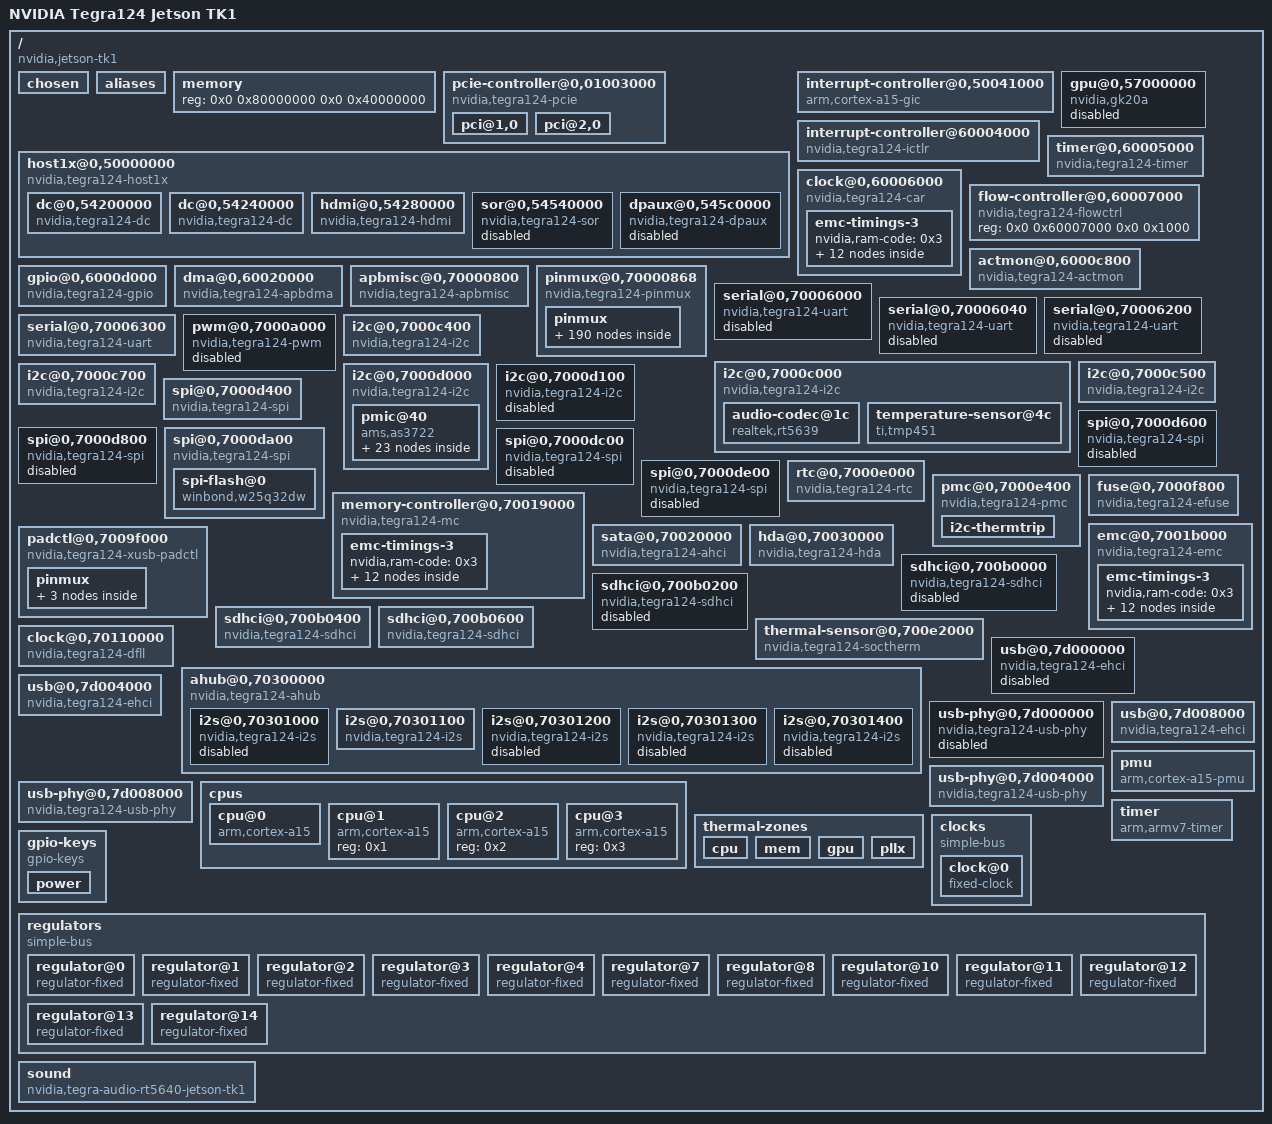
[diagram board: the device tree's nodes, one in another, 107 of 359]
/*
 * Modified from Linux device tree "arch/arm/boot/dts/tegra124-jetson-tk1.dts"
 *
 * The code contained herein is licensed under the GNU General Public
 * License. You may obtain a copy of the GNU General Public License
 * Version 2 or later at the following locations:
 *
 * http://www.opensource.org/licenses/gpl-license.html
 * http://www.gnu.org/copyleft/gpl.html
 *
 * @TAG(OTHER_GPL)
 */

/dts-v1/;

/ {
	#address-cells = <0x2>;
	#size-cells = <0x2>;
	compatible = "nvidia,jetson-tk1", "nvidia,tegra124";
	model = "NVIDIA Tegra124 Jetson TK1";
	interrupt-parent = <0x1>;

	chosen {
		bootargs = "console=ttyS0,115200n8 otf_key=c75e5bb91eb3bd947560357b64422f85 usbcore.old_scheme_first=1 tegraid=40.1.1.0.0 modem_id=0 android.kerneltype=normal commchip_id=0 usb_port_owner_info=2 lane_owner_info=1 touch_id=0@0 board_info=0x0177:0x0000:0x02:0x43:0x00 init=/sbin/init root=/dev/mmcblk0p2 rw rootwait gpt earlyprintk";
	};

	aliases {
		rtc0 = "/i2c@0,7000d000/pmic@40";
		rtc1 = "/rtc@0,7000e000";
		serial0 = "/serial@0,70006300";
	};

	memory {
		device_type = "memory";
		reg = <0x0 0x80000000 0x0 0x40000000>;
	};

	pcie-controller@0,01003000 {
		compatible = "nvidia,tegra124-pcie";
		device_type = "pci";
		reg = <0x0 0x1003000 0x0 0x800 0x0 0x1003800 0x0 0x800 0x0 0x2000000 0x0 0x10000000>;
		reg-names = "pads", "afi", "cs";
		interrupts = <0x0 0x62 0x4 0x0 0x63 0x4>;
		interrupt-names = "intr", "msi";
		#interrupt-cells = <0x1>;
		interrupt-map-mask = <0x0 0x0 0x0 0x0>;
		interrupt-map = <0x0 0x0 0x0 0x0 0x1 0x0 0x62 0x4>;
		bus-range = <0x0 0xff>;
		#address-cells = <0x3>;
		#size-cells = <0x2>;
		ranges = <0x82000000 0x0 0x1000000 0x0 0x1000000 0x0 0x1000 0x82000000 0x0 0x1001000 0x0 0x1001000 0x0 0x1000 0x81000000 0x0 0x0 0x0 0x12000000 0x0 0x10000 0x82000000 0x0 0x13000000 0x0 0x13000000 0x0 0xd000000 0xc2000000 0x0 0x20000000 0x0 0x20000000 0x0 0x20000000>;
		clocks = <0x2 0x46 0x2 0x48 0x2 0xe7 0x2 0x10c>;
		clock-names = "pex", "afi", "pll_e", "cml";
		resets = <0x2 0x46 0x2 0x48 0x2 0x4a>;
		reset-names = "pex", "afi", "pcie_x";
		status = "okay";
		phys = <0x3 0x0>;
		phy-names = "pcie";
		avddio-pex-supply = <0x4>;
		dvddio-pex-supply = <0x4>;
		avdd-pex-pll-supply = <0x4>;
		hvdd-pex-supply = <0x5>;
		hvdd-pex-pll-e-supply = <0x5>;
		vddio-pex-ctl-supply = <0x5>;
		avdd-pll-erefe-supply = <0x6>;

		pci@1,0 {
			device_type = "pci";
			assigned-addresses = <0x82000800 0x0 0x1000000 0x0 0x1000>;
			reg = <0x800 0x0 0x0 0x0 0x0>;
			status = "okay";
			#address-cells = <0x3>;
			#size-cells = <0x2>;
			ranges;
			nvidia,num-lanes = <0x2>;
		};

		pci@2,0 {
			device_type = "pci";
			assigned-addresses = <0x82001000 0x0 0x1001000 0x0 0x1000>;
			reg = <0x1000 0x0 0x0 0x0 0x0>;
			status = "okay";
			#address-cells = <0x3>;
			#size-cells = <0x2>;
			ranges;
			nvidia,num-lanes = <0x1>;
		};
	};

	host1x@0,50000000 {
		compatible = "nvidia,tegra124-host1x", "simple-bus";
		reg = <0x0 0x50000000 0x0 0x34000>;
		interrupts = <0x0 0x41 0x4 0x0 0x43 0x4>;
		clocks = <0x2 0x1c>;
		resets = <0x2 0x1c>;
		reset-names = "host1x";
		#address-cells = <0x2>;
		#size-cells = <0x2>;
		ranges = <0x0 0x54000000 0x0 0x54000000 0x0 0x1000000>;

		dc@0,54200000 {
			compatible = "nvidia,tegra124-dc";
			reg = <0x0 0x54200000 0x0 0x40000>;
			interrupts = <0x0 0x49 0x4>;
			clocks = <0x2 0x1b 0x2 0xd3>;
			clock-names = "dc", "parent";
			resets = <0x2 0x1b>;
			reset-names = "dc";
			iommus = <0x7 0x1>;
			nvidia,head = <0x0>;
		};

		dc@0,54240000 {
			compatible = "nvidia,tegra124-dc";
			reg = <0x0 0x54240000 0x0 0x40000>;
			interrupts = <0x0 0x4a 0x4>;
			clocks = <0x2 0x1a 0x2 0xd3>;
			clock-names = "dc", "parent";
			resets = <0x2 0x1a>;
			reset-names = "dc";
			iommus = <0x7 0x2>;
			nvidia,head = <0x1>;
		};

		hdmi@0,54280000 {
			compatible = "nvidia,tegra124-hdmi";
			reg = <0x0 0x54280000 0x0 0x40000>;
			interrupts = <0x0 0x4b 0x4>;
			clocks = <0x2 0x33 0x2 0xdd>;
			clock-names = "hdmi", "parent";
			resets = <0x2 0x33>;
			reset-names = "hdmi";
			status = "okay";
			hdmi-supply = <0x8>;
			pll-supply = <0x9>;
			vdd-supply = <0xa>;
			nvidia,ddc-i2c-bus = <0xb>;
			nvidia,hpd-gpio = <0xc 0x6f 0x0>;
		};

		sor@0,54540000 {
			compatible = "nvidia,tegra124-sor";
			reg = <0x0 0x54540000 0x0 0x40000>;
			interrupts = <0x0 0x4c 0x4>;
			clocks = <0x2 0xb6 0x2 0xdb 0x2 0x10f 0x2 0xc9>;
			clock-names = "sor", "parent", "dp", "safe";
			resets = <0x2 0xb6>;
			reset-names = "sor";
			status = "disabled";
		};

		dpaux@0,545c0000 {
			compatible = "nvidia,tegra124-dpaux";
			reg = <0x0 0x545c0000 0x0 0x40000>;
			interrupts = <0x0 0x9f 0x4>;
			clocks = <0x2 0xb5 0x2 0x10f>;
			clock-names = "dpaux", "parent";
			resets = <0x2 0xb5>;
			reset-names = "dpaux";
			status = "disabled";
		};
	};

	interrupt-controller@0,50041000 {
		compatible = "arm,cortex-a15-gic";
		#interrupt-cells = <0x3>;
		interrupt-controller;
		reg = <0x0 0x50041000 0x0 0x1000 0x0 0x50042000 0x0 0x1000 0x0 0x50044000 0x0 0x2000 0x0 0x50046000 0x0 0x2000>;
		interrupts = <0x1 0x9 0xf04>;
		interrupt-parent = <0x1>;
		linux,phandle = <0x1>;
		phandle = <0x1>;
	};

	gpu@0,57000000 {
		compatible = "nvidia,gk20a";
		reg = <0x0 0x57000000 0x0 0x1000000 0x0 0x58000000 0x0 0x1000000>;
		interrupts = <0x0 0x9d 0x4 0x0 0x9e 0x4>;
		interrupt-names = "stall", "nonstall";
		clocks = <0x2 0xb8 0x2 0x10b>;
		clock-names = "gpu", "pwr";
		resets = <0x2 0xb8>;
		reset-names = "gpu";
		iommus = <0x7 0x13>;
		status = "disabled";
	};

	interrupt-controller@60004000 {
		compatible = "nvidia,tegra124-ictlr", "nvidia,tegra30-ictlr";
		reg = <0x0 0x60004000 0x0 0x100 0x0 0x60004100 0x0 0x100 0x0 0x60004200 0x0 0x100 0x0 0x60004300 0x0 0x100 0x0 0x60004400 0x0 0x100>;
		interrupt-controller;
		#interrupt-cells = <0x3>;
		interrupt-parent = <0x1>;
	};

	timer@0,60005000 {
		compatible = "nvidia,tegra124-timer", "nvidia,tegra20-timer";
		reg = <0x0 0x60005000 0x0 0x400>;
		interrupts = <0x0 0x0 0x4 0x0 0x1 0x4 0x0 0x29 0x4 0x0 0x2a 0x4 0x0 0x79 0x4 0x0 0x7a 0x4>;
		clocks = <0x2 0x5>;
	};

	clock@0,60006000 {
		compatible = "nvidia,tegra124-car";
		reg = <0x0 0x60006000 0x0 0x1000>;
		#clock-cells = <0x1>;
		#reset-cells = <0x1>;
		nvidia,external-memory-controller = <0xd>;
		linux,phandle = <0x2>;
		phandle = <0x2>;

		emc-timings-3 {
			nvidia,ram-code = <0x3>;

			timing-12750000 {
				clock-frequency = <0xc28cb0>;
				nvidia,parent-clock-frequency = <0x18519600>;
				clocks = <0x2 0xd3>;
				clock-names = "emc-parent";
			};

			timing-20400000 {
				clock-frequency = <0x1374780>;
				nvidia,parent-clock-frequency = <0x18519600>;
				clocks = <0x2 0xd3>;
				clock-names = "emc-parent";
			};

			timing-40800000 {
				clock-frequency = <0x26e8f00>;
				nvidia,parent-clock-frequency = <0x18519600>;
				clocks = <0x2 0xd3>;
				clock-names = "emc-parent";
			};

			timing-68000000 {
				clock-frequency = <0x40d9900>;
				nvidia,parent-clock-frequency = <0x18519600>;
				clocks = <0x2 0xd3>;
				clock-names = "emc-parent";
			};

			timing-102000000 {
				clock-frequency = <0x6146580>;
				nvidia,parent-clock-frequency = <0x18519600>;
				clocks = <0x2 0xd3>;
				clock-names = "emc-parent";
			};

			timing-204000000 {
				clock-frequency = <0xc28cb00>;
				nvidia,parent-clock-frequency = <0x18519600>;
				clocks = <0x2 0xd3>;
				clock-names = "emc-parent";
			};

			timing-300000000 {
				clock-frequency = <0x11e1a300>;
				nvidia,parent-clock-frequency = <0x23c34600>;
				clocks = <0x2 0xcd>;
				clock-names = "emc-parent";
			};

			timing-396000000 {
				clock-frequency = <0x179a7b00>;
				nvidia,parent-clock-frequency = <0x2f34f600>;
				clocks = <0x2 0xd1>;
				clock-names = "emc-parent";
			};

			timing-528000000 {
				clock-frequency = <0x1f78a400>;
				nvidia,parent-clock-frequency = <0x1f78a400>;
				clocks = <0x2 0x139>;
				clock-names = "emc-parent";
			};

			timing-600000000 {
				clock-frequency = <0x23c34600>;
				nvidia,parent-clock-frequency = <0x23c34600>;
				clocks = <0x2 0x13a>;
				clock-names = "emc-parent";
			};

			timing-792000000 {
				clock-frequency = <0x2f34f600>;
				nvidia,parent-clock-frequency = <0x2f34f600>;
				clocks = <0x2 0x139>;
				clock-names = "emc-parent";
			};

			timing-924000000 {
				clock-frequency = <0x37131f00>;
				nvidia,parent-clock-frequency = <0x37131f00>;
				clocks = <0x2 0x139>;
				clock-names = "emc-parent";
			};
		};
	};

	flow-controller@0,60007000 {
		compatible = "nvidia,tegra124-flowctrl";
		reg = <0x0 0x60007000 0x0 0x1000>;
	};

	actmon@0,6000c800 {
		compatible = "nvidia,tegra124-actmon";
		reg = <0x0 0x6000c800 0x0 0x400>;
		interrupts = <0x0 0x2d 0x4>;
		clocks = <0x2 0x77 0x2 0x39>;
		clock-names = "actmon", "emc";
		resets = <0x2 0x77>;
		reset-names = "actmon";
	};

	gpio@0,6000d000 {
		compatible = "nvidia,tegra124-gpio", "nvidia,tegra30-gpio";
		reg = <0x0 0x6000d000 0x0 0x1000>;
		interrupts = <0x0 0x20 0x4 0x0 0x21 0x4 0x0 0x22 0x4 0x0 0x23 0x4 0x0 0x37 0x4 0x0 0x57 0x4 0x0 0x59 0x4 0x0 0x7d 0x4>;
		#gpio-cells = <0x2>;
		gpio-controller;
		#interrupt-cells = <0x2>;
		interrupt-controller;
		gpio-ranges = <0xe 0x0 0x0 0xfb>;
		linux,phandle = <0xc>;
		phandle = <0xc>;
	};

	dma@0,60020000 {
		compatible = "nvidia,tegra124-apbdma", "nvidia,tegra148-apbdma";
		reg = <0x0 0x60020000 0x0 0x1400>;
		interrupts = <0x0 0x68 0x4 0x0 0x69 0x4 0x0 0x6a 0x4 0x0 0x6b 0x4 0x0 0x6c 0x4 0x0 0x6d 0x4 0x0 0x6e 0x4 0x0 0x6f 0x4 0x0 0x70 0x4 0x0 0x71 0x4 0x0 0x72 0x4 0x0 0x73 0x4 0x0 0x74 0x4 0x0 0x75 0x4 0x0 0x76 0x4 0x0 0x77 0x4 0x0 0x80 0x4 0x0 0x81 0x4 0x0 0x82 0x4 0x0 0x83 0x4 0x0 0x84 0x4 0x0 0x85 0x4 0x0 0x86 0x4 0x0 0x87 0x4 0x0 0x88 0x4 0x0 0x89 0x4 0x0 0x8a 0x4 0x0 0x8b 0x4 0x0 0x8c 0x4 0x0 0x8d 0x4 0x0 0x8e 0x4 0x0 0x8f 0x4>;
		clocks = <0x2 0x22>;
		resets = <0x2 0x22>;
		reset-names = "dma";
		#dma-cells = <0x1>;
		linux,phandle = <0x10>;
		phandle = <0x10>;
	};

	apbmisc@0,70000800 {
		compatible = "nvidia,tegra124-apbmisc", "nvidia,tegra20-apbmisc";
		reg = <0x0 0x70000800 0x0 0x64 0x0 0x7000e864 0x0 0x4>;
	};

	pinmux@0,70000868 {
		compatible = "nvidia,tegra124-pinmux";
		reg = <0x0 0x70000868 0x0 0x164 0x0 0x70003000 0x0 0x434 0x0 0x70000820 0x0 0x8>;
		pinctrl-names = "boot";
		pinctrl-0 = <0xf>;
		linux,phandle = <0xe>;
		phandle = <0xe>;

		pinmux {
			linux,phandle = <0xf>;
			phandle = <0xf>;

			clk_32k_out_pa0 {
				nvidia,pins = "clk_32k_out_pa0";
				nvidia,function = "soc";
				nvidia,pull = <0x2>;
				nvidia,tristate = <0x1>;
				nvidia,enable-input = <0x1>;
			};

			uart3_cts_n_pa1 {
				nvidia,pins = "uart3_cts_n_pa1";
				nvidia,function = "gmi";
				nvidia,pull = <0x1>;
				nvidia,tristate = <0x1>;
				nvidia,enable-input = <0x0>;
			};

			dap2_fs_pa2 {
				nvidia,pins = "dap2_fs_pa2";
				nvidia,function = "i2s1";
				nvidia,pull = <0x0>;
				nvidia,tristate = <0x0>;
				nvidia,enable-input = <0x0>;
			};

			dap2_sclk_pa3 {
				nvidia,pins = "dap2_sclk_pa3";
				nvidia,function = "i2s1";
				nvidia,pull = <0x0>;
				nvidia,tristate = <0x0>;
				nvidia,enable-input = <0x0>;
			};

			dap2_din_pa4 {
				nvidia,pins = "dap2_din_pa4";
				nvidia,function = "i2s1";
				nvidia,pull = <0x0>;
				nvidia,tristate = <0x1>;
				nvidia,enable-input = <0x1>;
			};

			dap2_dout_pa5 {
				nvidia,pins = "dap2_dout_pa5";
				nvidia,function = "i2s1";
				nvidia,pull = <0x0>;
				nvidia,tristate = <0x0>;
				nvidia,enable-input = <0x0>;
			};

			sdmmc3_clk_pa6 {
				nvidia,pins = "sdmmc3_clk_pa6";
				nvidia,function = "sdmmc3";
				nvidia,pull = <0x0>;
				nvidia,tristate = <0x0>;
				nvidia,enable-input = <0x1>;
			};

			sdmmc3_cmd_pa7 {
				nvidia,pins = "sdmmc3_cmd_pa7";
				nvidia,function = "sdmmc3";
				nvidia,pull = <0x2>;
				nvidia,tristate = <0x0>;
				nvidia,enable-input = <0x1>;
			};

			pb0 {
				nvidia,pins = "pb0";
				nvidia,function = "uartd";
				nvidia,pull = <0x2>;
				nvidia,tristate = <0x1>;
				nvidia,enable-input = <0x1>;
			};

			pb1 {
				nvidia,pins = "pb1";
				nvidia,function = "uartd";
				nvidia,pull = <0x2>;
				nvidia,tristate = <0x1>;
				nvidia,enable-input = <0x1>;
			};

			sdmmc3_dat3_pb4 {
				nvidia,pins = "sdmmc3_dat3_pb4";
				nvidia,function = "sdmmc3";
				nvidia,pull = <0x2>;
				nvidia,tristate = <0x0>;
				nvidia,enable-input = <0x1>;
			};

			sdmmc3_dat2_pb5 {
				nvidia,pins = "sdmmc3_dat2_pb5";
				nvidia,function = "sdmmc3";
				nvidia,pull = <0x2>;
				nvidia,tristate = <0x0>;
				nvidia,enable-input = <0x1>;
			};

			sdmmc3_dat1_pb6 {
				nvidia,pins = "sdmmc3_dat1_pb6";
				nvidia,function = "sdmmc3";
				nvidia,pull = <0x2>;
				nvidia,tristate = <0x0>;
				nvidia,enable-input = <0x1>;
			};

			sdmmc3_dat0_pb7 {
				nvidia,pins = "sdmmc3_dat0_pb7";
				nvidia,function = "sdmmc3";
				nvidia,pull = <0x2>;
				nvidia,tristate = <0x0>;
				nvidia,enable-input = <0x1>;
			};

			uart3_rts_n_pc0 {
				nvidia,pins = "uart3_rts_n_pc0";
				nvidia,function = "gmi";
				nvidia,pull = <0x1>;
				nvidia,tristate = <0x1>;
				nvidia,enable-input = <0x0>;
			};

			uart2_txd_pc2 {
				nvidia,pins = "uart2_txd_pc2";
				nvidia,function = "irda";
				nvidia,pull = <0x0>;
				nvidia,tristate = <0x0>;
				nvidia,enable-input = <0x0>;
			};

			uart2_rxd_pc3 {
				nvidia,pins = "uart2_rxd_pc3";
				nvidia,function = "irda";
				nvidia,pull = <0x2>;
				nvidia,tristate = <0x1>;
				nvidia,enable-input = <0x1>;
			};

			gen1_i2c_scl_pc4 {
				nvidia,pins = "gen1_i2c_scl_pc4";
				nvidia,function = "i2c1";
				nvidia,pull = <0x0>;
				nvidia,tristate = <0x0>;
				nvidia,enable-input = <0x1>;
				nvidia,open-drain = <0x1>;
			};

			gen1_i2c_sda_pc5 {
				nvidia,pins = "gen1_i2c_sda_pc5";
				nvidia,function = "i2c1";
				nvidia,pull = <0x0>;
				nvidia,tristate = <0x0>;
				nvidia,enable-input = <0x1>;
				nvidia,open-drain = <0x1>;
			};

			pc7 {
				nvidia,pins = "pc7";
				nvidia,function = "rsvd1";
				nvidia,pull = <0x1>;
				nvidia,tristate = <0x1>;
				nvidia,enable-input = <0x0>;
			};

			pg0 {
				nvidia,pins = "pg0";
				nvidia,pull = <0x0>;
				nvidia,tristate = <0x1>;
				nvidia,enable-input = <0x1>;
			};

			pg1 {
				nvidia,pins = "pg1";
				nvidia,pull = <0x0>;
				nvidia,tristate = <0x1>;
				nvidia,enable-input = <0x1>;
			};

			pg2 {
				nvidia,pins = "pg2";
				nvidia,pull = <0x0>;
				nvidia,tristate = <0x1>;
				nvidia,enable-input = <0x1>;
			};

			pg3 {
				nvidia,pins = "pg3";
				nvidia,pull = <0x0>;
				nvidia,tristate = <0x1>;
				nvidia,enable-input = <0x1>;
			};

			pg4 {
				nvidia,pins = "pg4";
				nvidia,pull = <0x0>;
				nvidia,tristate = <0x1>;
				nvidia,enable-input = <0x1>;
			};

			pg5 {
				nvidia,pins = "pg5";
				nvidia,function = "spi4";
				nvidia,pull = <0x0>;
				nvidia,tristate = <0x0>;
				nvidia,enable-input = <0x0>;
			};

			pg6 {
				nvidia,pins = "pg6";
				nvidia,function = "spi4";
				nvidia,pull = <0x0>;
				nvidia,tristate = <0x0>;
				nvidia,enable-input = <0x0>;
			};

			pg7 {
				nvidia,pins = "pg7";
				nvidia,function = "spi4";
				nvidia,pull = <0x0>;
				nvidia,tristate = <0x1>;
				nvidia,enable-input = <0x1>;
			};

			ph0 {
				nvidia,pins = "ph0";
				nvidia,function = "gmi";
				nvidia,pull = <0x1>;
				nvidia,tristate = <0x1>;
				nvidia,enable-input = <0x0>;
			};

			ph1 {
				nvidia,pins = "ph1";
				nvidia,function = "pwm1";
				nvidia,pull = <0x0>;
				nvidia,tristate = <0x0>;
				nvidia,enable-input = <0x0>;
			};

			ph2 {
				nvidia,pins = "ph2";
				nvidia,pull = <0x0>;
				nvidia,tristate = <0x0>;
				nvidia,enable-input = <0x0>;
			};

			ph3 {
				nvidia,pins = "ph3";
				nvidia,function = "gmi";
				nvidia,pull = <0x1>;
				nvidia,tristate = <0x1>;
				nvidia,enable-input = <0x0>;
			};

			ph4 {
				nvidia,pins = "ph4";
				nvidia,pull = <0x0>;
				nvidia,tristate = <0x1>;
				nvidia,enable-input = <0x1>;
			};

			ph5 {
				nvidia,pins = "ph5";
				nvidia,function = "rsvd2";
				nvidia,pull = <0x1>;
				nvidia,tristate = <0x1>;
				nvidia,enable-input = <0x0>;
			};

			ph6 {
				nvidia,pins = "ph6";
				nvidia,function = "gmi";
				nvidia,pull = <0x1>;
				nvidia,tristate = <0x1>;
				nvidia,enable-input = <0x0>;
			};

			ph7 {
				nvidia,pins = "ph7";
				nvidia,pull = <0x0>;
				nvidia,tristate = <0x0>;
				nvidia,enable-input = <0x1>;
			};

			pi0 {
				nvidia,pins = "pi0";
				nvidia,pull = <0x0>;
				nvidia,tristate = <0x0>;
				nvidia,enable-input = <0x0>;
			};

			pi1 {
				nvidia,pins = "pi1";
				nvidia,pull = <0x0>;
				nvidia,tristate = <0x1>;
				nvidia,enable-input = <0x1>;
			};

			pi2 {
				nvidia,pins = "pi2";
				nvidia,function = "rsvd4";
				nvidia,pull = <0x1>;
				nvidia,tristate = <0x1>;
				nvidia,enable-input = <0x0>;
			};

			pi3 {
				nvidia,pins = "pi3";
				nvidia,function = "spi4";
				nvidia,pull = <0x0>;
				nvidia,tristate = <0x0>;
				nvidia,enable-input = <0x0>;
			};

			pi4 {
				nvidia,pins = "pi4";
				nvidia,function = "gmi";
				nvidia,pull = <0x1>;
				nvidia,tristate = <0x1>;
				nvidia,enable-input = <0x0>;
			};

			pi5 {
				nvidia,pins = "pi5";
				nvidia,function = "rsvd2";
				nvidia,pull = <0x1>;
				nvidia,tristate = <0x1>;
				nvidia,enable-input = <0x0>;
			};

			pi6 {
				nvidia,pins = "pi6";
				nvidia,pull = <0x0>;
				nvidia,tristate = <0x1>;
				nvidia,enable-input = <0x1>;
			};

			pi7 {
				nvidia,pins = "pi7";
				nvidia,function = "rsvd1";
				nvidia,pull = <0x1>;
				nvidia,tristate = <0x1>;
				nvidia,enable-input = <0x0>;
			};

			pj0 {
				nvidia,pins = "pj0";
				nvidia,pull = <0x0>;
				nvidia,tristate = <0x1>;
				nvidia,enable-input = <0x1>;
			};

			pj2 {
				nvidia,pins = "pj2";
				nvidia,function = "rsvd1";
				nvidia,pull = <0x1>;
				nvidia,tristate = <0x1>;
				nvidia,enable-input = <0x0>;
			};

			uart2_cts_n_pj5 {
				nvidia,pins = "uart2_cts_n_pj5";
				nvidia,function = "uartb";
				nvidia,pull = <0x2>;
				nvidia,tristate = <0x1>;
				nvidia,enable-input = <0x1>;
			};

			uart2_rts_n_pj6 {
				nvidia,pins = "uart2_rts_n_pj6";
				nvidia,function = "uartb";
				nvidia,pull = <0x0>;
				nvidia,tristate = <0x0>;
				nvidia,enable-input = <0x0>;
			};

			pj7 {
				nvidia,pins = "pj7";
				nvidia,function = "uartd";
				nvidia,pull = <0x0>;
				nvidia,tristate = <0x0>;
				nvidia,enable-input = <0x0>;
			};

			pk0 {
				nvidia,pins = "pk0";
				nvidia,function = "rsvd1";
				nvidia,pull = <0x1>;
				nvidia,tristate = <0x1>;
				nvidia,enable-input = <0x0>;
			};

			pk1 {
				nvidia,pins = "pk1";
				nvidia,pull = <0x0>;
				nvidia,tristate = <0x0>;
				nvidia,enable-input = <0x0>;
			};

			pk2 {
				nvidia,pins = "pk2";
				nvidia,pull = <0x0>;
				nvidia,tristate = <0x0>;
				nvidia,enable-input = <0x1>;
			};

			pk3 {
				nvidia,pins = "pk3";
				nvidia,function = "gmi";
				nvidia,pull = <0x1>;
				nvidia,tristate = <0x1>;
				nvidia,enable-input = <0x0>;
			};

			pk4 {
				nvidia,pins = "pk4";
				nvidia,pull = <0x0>;
				nvidia,tristate = <0x0>;
				nvidia,enable-input = <0x0>;
			};

			spdif_out_pk5 {
				nvidia,pins = "spdif_out_pk5";
				nvidia,function = "rsvd2";
				nvidia,pull = <0x1>;
				nvidia,tristate = <0x1>;
				nvidia,enable-input = <0x0>;
			};

			spdif_in_pk6 {
				nvidia,pins = "spdif_in_pk6";
				nvidia,pull = <0x0>;
				nvidia,tristate = <0x0>;
				nvidia,enable-input = <0x0>;
			};

			pk7 {
				nvidia,pins = "pk7";
				nvidia,function = "uartd";
				nvidia,pull = <0x0>;
				nvidia,tristate = <0x0>;
				nvidia,enable-input = <0x0>;
			};

			dap1_fs_pn0 {
				nvidia,pins = "dap1_fs_pn0";
				nvidia,function = "rsvd4";
				nvidia,pull = <0x1>;
				nvidia,tristate = <0x1>;
				nvidia,enable-input = <0x0>;
			};

			dap1_din_pn1 {
				nvidia,pins = "dap1_din_pn1";
				nvidia,function = "rsvd4";
				nvidia,pull = <0x1>;
				nvidia,tristate = <0x1>;
				nvidia,enable-input = <0x0>;
			};

			dap1_dout_pn2 {
				nvidia,pins = "dap1_dout_pn2";
				nvidia,function = "sata";
				nvidia,pull = <0x0>;
				nvidia,tristate = <0x0>;
				nvidia,enable-input = <0x0>;
			};

			dap1_sclk_pn3 {
				nvidia,pins = "dap1_sclk_pn3";
				nvidia,function = "rsvd4";
				nvidia,pull = <0x1>;
				nvidia,tristate = <0x1>;
				nvidia,enable-input = <0x0>;
			};

			usb_vbus_en0_pn4 {
				nvidia,pins = "usb_vbus_en0_pn4";
				nvidia,function = "usb";
				nvidia,pull = <0x0>;
				nvidia,tristate = <0x0>;
				nvidia,enable-input = <0x1>;
				nvidia,open-drain = <0x0>;
			};

			usb_vbus_en1_pn5 {
				nvidia,pins = "usb_vbus_en1_pn5";
				nvidia,function = "usb";
				nvidia,pull = <0x0>;
				nvidia,tristate = <0x0>;
				nvidia,enable-input = <0x1>;
				nvidia,open-drain = <0x0>;
			};

			hdmi_int_pn7 {
				nvidia,pins = "hdmi_int_pn7";
				nvidia,pull = <0x1>;
				nvidia,tristate = <0x1>;
				nvidia,enable-input = <0x1>;
				nvidia,rcv-sel = <0x0>;
			};

			ulpi_data7_po0 {
				nvidia,pins = "ulpi_data7_po0";
				nvidia,function = "ulpi";
				nvidia,pull = <0x1>;
				nvidia,tristate = <0x1>;
				nvidia,enable-input = <0x0>;
			};

			ulpi_data0_po1 {
				nvidia,pins = "ulpi_data0_po1";
				nvidia,pull = <0x0>;
				nvidia,tristate = <0x1>;
				nvidia,enable-input = <0x1>;
			};

			ulpi_data1_po2 {
				nvidia,pins = "ulpi_data1_po2";
				nvidia,function = "ulpi";
				nvidia,pull = <0x1>;
				nvidia,tristate = <0x1>;
				nvidia,enable-input = <0x0>;
			};

			ulpi_data2_po3 {
				nvidia,pins = "ulpi_data2_po3";
				nvidia,function = "ulpi";
				nvidia,pull = <0x1>;
				nvidia,tristate = <0x1>;
				nvidia,enable-input = <0x0>;
			};

			ulpi_data3_po4 {
				nvidia,pins = "ulpi_data3_po4";
				nvidia,pull = <0x0>;
				nvidia,tristate = <0x1>;
				nvidia,enable-input = <0x1>;
			};

			ulpi_data4_po5 {
				nvidia,pins = "ulpi_data4_po5";
				nvidia,function = "ulpi";
				nvidia,pull = <0x1>;
				nvidia,tristate = <0x1>;
				nvidia,enable-input = <0x0>;
			};

			ulpi_data5_po6 {
				nvidia,pins = "ulpi_data5_po6";
				nvidia,function = "ulpi";
				nvidia,pull = <0x1>;
				nvidia,tristate = <0x1>;
				nvidia,enable-input = <0x0>;
			};

			ulpi_data6_po7 {
				nvidia,pins = "ulpi_data6_po7";
				nvidia,function = "ulpi";
				nvidia,pull = <0x1>;
				nvidia,tristate = <0x1>;
				nvidia,enable-input = <0x0>;
			};

			dap3_fs_pp0 {
				nvidia,pins = "dap3_fs_pp0";
				nvidia,function = "i2s2";
				nvidia,pull = <0x1>;
				nvidia,tristate = <0x1>;
				nvidia,enable-input = <0x0>;
			};

			dap3_din_pp1 {
				nvidia,pins = "dap3_din_pp1";
				nvidia,function = "i2s2";
				nvidia,pull = <0x1>;
				nvidia,tristate = <0x1>;
				nvidia,enable-input = <0x0>;
			};

			dap3_dout_pp2 {
				nvidia,pins = "dap3_dout_pp2";
				nvidia,pull = <0x0>;
				nvidia,tristate = <0x0>;
				nvidia,enable-input = <0x0>;
			};

			dap3_sclk_pp3 {
				nvidia,pins = "dap3_sclk_pp3";
				nvidia,function = "rsvd3";
				nvidia,pull = <0x1>;
				nvidia,tristate = <0x1>;
				nvidia,enable-input = <0x0>;
			};

			dap4_fs_pp4 {
				nvidia,pins = "dap4_fs_pp4";
				nvidia,function = "rsvd4";
				nvidia,pull = <0x1>;
				nvidia,tristate = <0x1>;
				nvidia,enable-input = <0x0>;
			};

			dap4_din_pp5 {
				nvidia,pins = "dap4_din_pp5";
				nvidia,function = "rsvd3";
				nvidia,pull = <0x1>;
				nvidia,tristate = <0x1>;
				nvidia,enable-input = <0x0>;
			};

			dap4_dout_pp6 {
				nvidia,pins = "dap4_dout_pp6";
				nvidia,function = "rsvd4";
				nvidia,pull = <0x1>;
				nvidia,tristate = <0x1>;
				nvidia,enable-input = <0x0>;
			};

			dap4_sclk_pp7 {
				nvidia,pins = "dap4_sclk_pp7";
				nvidia,function = "rsvd3";
				nvidia,pull = <0x1>;
				nvidia,tristate = <0x1>;
				nvidia,enable-input = <0x0>;
			};

			kb_col0_pq0 {
				nvidia,pins = "kb_col0_pq0";
				nvidia,pull = <0x2>;
				nvidia,tristate = <0x1>;
				nvidia,enable-input = <0x1>;
			};

			kb_col1_pq1 {
				nvidia,pins = "kb_col1_pq1";
				nvidia,function = "rsvd2";
				nvidia,pull = <0x1>;
				nvidia,tristate = <0x1>;
				nvidia,enable-input = <0x0>;
			};

			kb_col2_pq2 {
				nvidia,pins = "kb_col2_pq2";
				nvidia,function = "rsvd2";
				nvidia,pull = <0x1>;
				nvidia,tristate = <0x1>;
				nvidia,enable-input = <0x0>;
			};

			kb_col3_pq3 {
				nvidia,pins = "kb_col3_pq3";
				nvidia,pull = <0x0>;
				nvidia,tristate = <0x1>;
				nvidia,enable-input = <0x1>;
			};

			kb_col4_pq4 {
				nvidia,pins = "kb_col4_pq4";
				nvidia,function = "sdmmc3";
				nvidia,pull = <0x2>;
				nvidia,tristate = <0x1>;
				nvidia,enable-input = <0x1>;
			};

			kb_col5_pq5 {
				nvidia,pins = "kb_col5_pq5";
				nvidia,pull = <0x0>;
				nvidia,tristate = <0x1>;
				nvidia,enable-input = <0x1>;
			};

			kb_col6_pq6 {
				nvidia,pins = "kb_col6_pq6";
				nvidia,function = "rsvd2";
				nvidia,pull = <0x1>;
				nvidia,tristate = <0x1>;
				nvidia,enable-input = <0x0>;
			};

			kb_col7_pq7 {
				nvidia,pins = "kb_col7_pq7";
				nvidia,function = "rsvd2";
				nvidia,pull = <0x1>;
				nvidia,tristate = <0x1>;
				nvidia,enable-input = <0x0>;
			};

			kb_row0_pr0 {
				nvidia,pins = "kb_row0_pr0";
				nvidia,pull = <0x0>;
				nvidia,tristate = <0x0>;
				nvidia,enable-input = <0x0>;
			};

			kb_row1_pr1 {
				nvidia,pins = "kb_row1_pr1";
				nvidia,function = "rsvd2";
				nvidia,pull = <0x1>;
				nvidia,tristate = <0x1>;
				nvidia,enable-input = <0x0>;
			};

			kb_row2_pr2 {
				nvidia,pins = "kb_row2_pr2";
				nvidia,pull = <0x0>;
				nvidia,tristate = <0x0>;
				nvidia,enable-input = <0x0>;
			};

			kb_row3_pr3 {
				nvidia,pins = "kb_row3_pr3";
				nvidia,function = "kbc";
				nvidia,pull = <0x1>;
				nvidia,tristate = <0x1>;
				nvidia,enable-input = <0x0>;
			};

			kb_row4_pr4 {
				nvidia,pins = "kb_row4_pr4";
				nvidia,pull = <0x0>;
				nvidia,tristate = <0x1>;
				nvidia,enable-input = <0x1>;
			};

			kb_row5_pr5 {
				nvidia,pins = "kb_row5_pr5";
				nvidia,function = "rsvd3";
				nvidia,pull = <0x1>;
				nvidia,tristate = <0x1>;
				nvidia,enable-input = <0x0>;
			};

			kb_row6_pr6 {
				nvidia,pins = "kb_row6_pr6";
				nvidia,function = "displaya_alt";
				nvidia,pull = <0x0>;
				nvidia,tristate = <0x1>;
				nvidia,enable-input = <0x1>;
			};

			kb_row7_pr7 {
				nvidia,pins = "kb_row7_pr7";
				nvidia,pull = <0x0>;
				nvidia,tristate = <0x1>;
				nvidia,enable-input = <0x1>;
			};

			kb_row8_ps0 {
				nvidia,pins = "kb_row8_ps0";
				nvidia,function = "rsvd2";
				nvidia,pull = <0x1>;
				nvidia,tristate = <0x1>;
				nvidia,enable-input = <0x0>;
			};

			kb_row9_ps1 {
				nvidia,pins = "kb_row9_ps1";
				nvidia,function = "uarta";
				nvidia,pull = <0x0>;
				nvidia,tristate = <0x0>;
				nvidia,enable-input = <0x0>;
			};

			kb_row10_ps2 {
				nvidia,pins = "kb_row10_ps2";
				nvidia,function = "uarta";
				nvidia,pull = <0x2>;
				nvidia,tristate = <0x1>;
				nvidia,enable-input = <0x1>;
			};

			kb_row11_ps3 {
				nvidia,pins = "kb_row11_ps3";
				nvidia,function = "rsvd2";
				nvidia,pull = <0x1>;
				nvidia,tristate = <0x1>;
				nvidia,enable-input = <0x0>;
			};

			kb_row12_ps4 {
				nvidia,pins = "kb_row12_ps4";
				nvidia,function = "rsvd2";
				nvidia,pull = <0x1>;
				nvidia,tristate = <0x1>;
				nvidia,enable-input = <0x0>;
			};

			kb_row13_ps5 {
				nvidia,pins = "kb_row13_ps5";
				nvidia,function = "rsvd2";
				nvidia,pull = <0x1>;
				nvidia,tristate = <0x1>;
				nvidia,enable-input = <0x0>;
			};

			kb_row14_ps6 {
				nvidia,pins = "kb_row14_ps6";
				nvidia,function = "rsvd2";
				nvidia,pull = <0x1>;
				nvidia,tristate = <0x1>;
				nvidia,enable-input = <0x0>;
			};

			kb_row15_ps7 {
				nvidia,pins = "kb_row15_ps7";
				nvidia,pull = <0x0>;
				nvidia,tristate = <0x1>;
				nvidia,enable-input = <0x1>;
			};

			kb_row16_pt0 {
				nvidia,pins = "kb_row16_pt0";
				nvidia,pull = <0x0>;
				nvidia,tristate = <0x0>;
				nvidia,enable-input = <0x0>;
			};

			kb_row17_pt1 {
				nvidia,pins = "kb_row17_pt1";
				nvidia,pull = <0x0>;
				nvidia,tristate = <0x1>;
				nvidia,enable-input = <0x1>;
			};

			gen2_i2c_scl_pt5 {
				nvidia,pins = "gen2_i2c_scl_pt5";
				nvidia,function = "i2c2";
				nvidia,pull = <0x0>;
				nvidia,tristate = <0x0>;
				nvidia,enable-input = <0x1>;
				nvidia,open-drain = <0x1>;
			};

			gen2_i2c_sda_pt6 {
				nvidia,pins = "gen2_i2c_sda_pt6";
				nvidia,function = "i2c2";
				nvidia,pull = <0x0>;
				nvidia,tristate = <0x0>;
				nvidia,enable-input = <0x1>;
				nvidia,open-drain = <0x1>;
			};

			sdmmc4_cmd_pt7 {
				nvidia,pins = "sdmmc4_cmd_pt7";
				nvidia,function = "sdmmc4";
				nvidia,pull = <0x2>;
				nvidia,tristate = <0x0>;
				nvidia,enable-input = <0x1>;
			};

			pu0 {
				nvidia,pins = "pu0";
				nvidia,pull = <0x0>;
				nvidia,tristate = <0x0>;
				nvidia,enable-input = <0x1>;
			};

			pu1 {
				nvidia,pins = "pu1";
				nvidia,pull = <0x0>;
				nvidia,tristate = <0x0>;
				nvidia,enable-input = <0x1>;
			};

			pu2 {
				nvidia,pins = "pu2";
				nvidia,pull = <0x0>;
				nvidia,tristate = <0x0>;
				nvidia,enable-input = <0x1>;
			};

			pu3 {
				nvidia,pins = "pu3";
				nvidia,pull = <0x0>;
				nvidia,tristate = <0x0>;
				nvidia,enable-input = <0x1>;
			};

			pu4 {
				nvidia,pins = "pu4";
				nvidia,pull = <0x0>;
				nvidia,tristate = <0x0>;
				nvidia,enable-input = <0x1>;
			};

			pu5 {
				nvidia,pins = "pu5";
				nvidia,pull = <0x0>;
				nvidia,tristate = <0x0>;
				nvidia,enable-input = <0x1>;
			};

			pu6 {
				nvidia,pins = "pu6";
				nvidia,pull = <0x0>;
				nvidia,tristate = <0x0>;
				nvidia,enable-input = <0x1>;
			};

			pv0 {
				nvidia,pins = "pv0";
				nvidia,pull = <0x0>;
				nvidia,tristate = <0x1>;
				nvidia,enable-input = <0x1>;
			};

			pv1 {
				nvidia,pins = "pv1";
				nvidia,pull = <0x0>;
				nvidia,tristate = <0x1>;
				nvidia,enable-input = <0x1>;
			};

			sdmmc3_cd_n_pv2 {
				nvidia,pins = "sdmmc3_cd_n_pv2";
				nvidia,function = "sdmmc3";
				nvidia,pull = <0x2>;
				nvidia,tristate = <0x1>;
				nvidia,enable-input = <0x1>;
			};

			sdmmc1_wp_n_pv3 {
				nvidia,pins = "sdmmc1_wp_n_pv3";
				nvidia,function = "sdmmc1";
				nvidia,pull = <0x1>;
				nvidia,tristate = <0x1>;
				nvidia,enable-input = <0x0>;
			};

			ddc_scl_pv4 {
				nvidia,pins = "ddc_scl_pv4";
				nvidia,function = "i2c4";
				nvidia,pull = <0x0>;
				nvidia,tristate = <0x0>;
				nvidia,enable-input = <0x1>;
				nvidia,rcv-sel = <0x0>;
			};

			ddc_sda_pv5 {
				nvidia,pins = "ddc_sda_pv5";
				nvidia,function = "i2c4";
				nvidia,pull = <0x0>;
				nvidia,tristate = <0x0>;
				nvidia,enable-input = <0x1>;
				nvidia,rcv-sel = <0x0>;
			};

			gpio_w2_aud_pw2 {
				nvidia,pins = "gpio_w2_aud_pw2";
				nvidia,function = "rsvd2";
				nvidia,pull = <0x1>;
				nvidia,tristate = <0x1>;
				nvidia,enable-input = <0x0>;
			};

			gpio_w3_aud_pw3 {
				nvidia,pins = "gpio_w3_aud_pw3";
				nvidia,function = "spi6";
				nvidia,pull = <0x1>;
				nvidia,tristate = <0x1>;
				nvidia,enable-input = <0x0>;
			};

			dap_mclk1_pw4 {
				nvidia,pins = "dap_mclk1_pw4";
				nvidia,function = "extperiph1";
				nvidia,pull = <0x0>;
				nvidia,tristate = <0x0>;
				nvidia,enable-input = <0x0>;
			};

			clk2_out_pw5 {
				nvidia,pins = "clk2_out_pw5";
				nvidia,function = "extperiph2";
				nvidia,pull = <0x0>;
				nvidia,tristate = <0x0>;
				nvidia,enable-input = <0x0>;
			};

			uart3_txd_pw6 {
				nvidia,pins = "uart3_txd_pw6";
				nvidia,function = "rsvd2";
				nvidia,pull = <0x1>;
				nvidia,tristate = <0x1>;
				nvidia,enable-input = <0x0>;
			};

			uart3_rxd_pw7 {
				nvidia,pins = "uart3_rxd_pw7";
				nvidia,function = "rsvd2";
				nvidia,pull = <0x1>;
				nvidia,tristate = <0x1>;
				nvidia,enable-input = <0x0>;
			};

			dvfs_pwm_px0 {
				nvidia,pins = "dvfs_pwm_px0";
				nvidia,function = "cldvfs";
				nvidia,pull = <0x0>;
				nvidia,tristate = <0x0>;
				nvidia,enable-input = <0x0>;
			};

			gpio_x1_aud_px1 {
				nvidia,pins = "gpio_x1_aud_px1";
				nvidia,pull = <0x0>;
				nvidia,tristate = <0x1>;
				nvidia,enable-input = <0x1>;
			};

			dvfs_clk_px2 {
				nvidia,pins = "dvfs_clk_px2";
				nvidia,function = "cldvfs";
				nvidia,pull = <0x0>;
				nvidia,tristate = <0x0>;
				nvidia,enable-input = <0x0>;
			};

			gpio_x3_aud_px3 {
				nvidia,pins = "gpio_x3_aud_px3";
				nvidia,function = "rsvd4";
				nvidia,pull = <0x1>;
				nvidia,tristate = <0x1>;
				nvidia,enable-input = <0x0>;
			};

			gpio_x4_aud_px4 {
				nvidia,pins = "gpio_x4_aud_px4";
				nvidia,pull = <0x0>;
				nvidia,tristate = <0x1>;
				nvidia,enable-input = <0x1>;
			};

			gpio_x5_aud_px5 {
				nvidia,pins = "gpio_x5_aud_px5";
				nvidia,function = "rsvd4";
				nvidia,pull = <0x1>;
				nvidia,tristate = <0x1>;
				nvidia,enable-input = <0x0>;
			};

			gpio_x6_aud_px6 {
				nvidia,pins = "gpio_x6_aud_px6";
				nvidia,function = "gmi";
				nvidia,pull = <0x1>;
				nvidia,tristate = <0x1>;
				nvidia,enable-input = <0x0>;
			};

			gpio_x7_aud_px7 {
				nvidia,pins = "gpio_x7_aud_px7";
				nvidia,pull = <0x0>;
				nvidia,tristate = <0x0>;
				nvidia,enable-input = <0x0>;
			};

			ulpi_clk_py0 {
				nvidia,pins = "ulpi_clk_py0";
				nvidia,function = "spi1";
				nvidia,pull = <0x0>;
				nvidia,tristate = <0x0>;
				nvidia,enable-input = <0x0>;
			};

			ulpi_dir_py1 {
				nvidia,pins = "ulpi_dir_py1";
				nvidia,function = "spi1";
				nvidia,pull = <0x0>;
				nvidia,tristate = <0x1>;
				nvidia,enable-input = <0x1>;
			};

			ulpi_nxt_py2 {
				nvidia,pins = "ulpi_nxt_py2";
				nvidia,function = "spi1";
				nvidia,pull = <0x0>;
				nvidia,tristate = <0x0>;
				nvidia,enable-input = <0x0>;
			};

			ulpi_stp_py3 {
				nvidia,pins = "ulpi_stp_py3";
				nvidia,function = "spi1";
				nvidia,pull = <0x0>;
				nvidia,tristate = <0x0>;
				nvidia,enable-input = <0x0>;
			};

			sdmmc1_dat3_py4 {
				nvidia,pins = "sdmmc1_dat3_py4";
				nvidia,function = "sdmmc1";
				nvidia,pull = <0x1>;
				nvidia,tristate = <0x1>;
				nvidia,enable-input = <0x0>;
			};

			sdmmc1_dat2_py5 {
				nvidia,pins = "sdmmc1_dat2_py5";
				nvidia,function = "sdmmc1";
				nvidia,pull = <0x1>;
				nvidia,tristate = <0x1>;
				nvidia,enable-input = <0x0>;
			};

			sdmmc1_dat1_py6 {
				nvidia,pins = "sdmmc1_dat1_py6";
				nvidia,function = "sdmmc1";
				nvidia,pull = <0x1>;
				nvidia,tristate = <0x1>;
				nvidia,enable-input = <0x0>;
			};

			sdmmc1_dat0_py7 {
				nvidia,pins = "sdmmc1_dat0_py7";
				nvidia,function = "rsvd2";
				nvidia,pull = <0x1>;
				nvidia,tristate = <0x1>;
				nvidia,enable-input = <0x0>;
			};

			sdmmc1_clk_pz0 {
				nvidia,pins = "sdmmc1_clk_pz0";
				nvidia,function = "rsvd3";
				nvidia,pull = <0x1>;
				nvidia,tristate = <0x1>;
				nvidia,enable-input = <0x0>;
			};

			sdmmc1_cmd_pz1 {
				nvidia,pins = "sdmmc1_cmd_pz1";
				nvidia,function = "sdmmc1";
				nvidia,pull = <0x1>;
				nvidia,tristate = <0x1>;
				nvidia,enable-input = <0x0>;
			};

			pwr_i2c_scl_pz6 {
				nvidia,pins = "pwr_i2c_scl_pz6";
				nvidia,function = "i2cpwr";
				nvidia,pull = <0x0>;
				nvidia,tristate = <0x0>;
				nvidia,enable-input = <0x1>;
				nvidia,open-drain = <0x1>;
			};

			pwr_i2c_sda_pz7 {
				nvidia,pins = "pwr_i2c_sda_pz7";
				nvidia,function = "i2cpwr";
				nvidia,pull = <0x0>;
				nvidia,tristate = <0x0>;
				nvidia,enable-input = <0x1>;
				nvidia,open-drain = <0x1>;
			};

			sdmmc4_dat0_paa0 {
				nvidia,pins = "sdmmc4_dat0_paa0";
				nvidia,function = "sdmmc4";
				nvidia,pull = <0x2>;
				nvidia,tristate = <0x0>;
				nvidia,enable-input = <0x1>;
			};

			sdmmc4_dat1_paa1 {
				nvidia,pins = "sdmmc4_dat1_paa1";
				nvidia,function = "sdmmc4";
				nvidia,pull = <0x2>;
				nvidia,tristate = <0x0>;
				nvidia,enable-input = <0x1>;
			};

			sdmmc4_dat2_paa2 {
				nvidia,pins = "sdmmc4_dat2_paa2";
				nvidia,function = "sdmmc4";
				nvidia,pull = <0x2>;
				nvidia,tristate = <0x0>;
				nvidia,enable-input = <0x1>;
			};

			sdmmc4_dat3_paa3 {
				nvidia,pins = "sdmmc4_dat3_paa3";
				nvidia,function = "sdmmc4";
				nvidia,pull = <0x2>;
				nvidia,tristate = <0x0>;
				nvidia,enable-input = <0x1>;
			};

			sdmmc4_dat4_paa4 {
				nvidia,pins = "sdmmc4_dat4_paa4";
				nvidia,function = "sdmmc4";
				nvidia,pull = <0x2>;
				nvidia,tristate = <0x0>;
				nvidia,enable-input = <0x1>;
			};

			sdmmc4_dat5_paa5 {
				nvidia,pins = "sdmmc4_dat5_paa5";
				nvidia,function = "sdmmc4";
				nvidia,pull = <0x2>;
				nvidia,tristate = <0x0>;
				nvidia,enable-input = <0x1>;
			};

			sdmmc4_dat6_paa6 {
				nvidia,pins = "sdmmc4_dat6_paa6";
				nvidia,function = "sdmmc4";
				nvidia,pull = <0x2>;
				nvidia,tristate = <0x0>;
				nvidia,enable-input = <0x1>;
			};

			sdmmc4_dat7_paa7 {
				nvidia,pins = "sdmmc4_dat7_paa7";
				nvidia,function = "sdmmc4";
				nvidia,pull = <0x2>;
				nvidia,tristate = <0x0>;
				nvidia,enable-input = <0x1>;
			};

			pbb0 {
				nvidia,pins = "pbb0";
				nvidia,function = "vimclk2_alt";
				nvidia,pull = <0x0>;
				nvidia,tristate = <0x0>;
				nvidia,enable-input = <0x0>;
			};

			cam_i2c_scl_pbb1 {
				nvidia,pins = "cam_i2c_scl_pbb1";
				nvidia,function = "i2c3";
				nvidia,pull = <0x0>;
				nvidia,tristate = <0x0>;
				nvidia,enable-input = <0x1>;
				nvidia,open-drain = <0x1>;
			};

			cam_i2c_sda_pbb2 {
				nvidia,pins = "cam_i2c_sda_pbb2";
				nvidia,function = "i2c3";
				nvidia,pull = <0x0>;
				nvidia,tristate = <0x0>;
				nvidia,enable-input = <0x1>;
				nvidia,open-drain = <0x1>;
			};

			pbb3 {
				nvidia,pins = "pbb3";
				nvidia,pull = <0x0>;
				nvidia,tristate = <0x0>;
				nvidia,enable-input = <0x0>;
			};

			pbb4 {
				nvidia,pins = "pbb4";
				nvidia,function = "vgp4";
				nvidia,pull = <0x0>;
				nvidia,tristate = <0x0>;
				nvidia,enable-input = <0x0>;
			};

			pbb5 {
				nvidia,pins = "pbb5";
				nvidia,pull = <0x0>;
				nvidia,tristate = <0x0>;
				nvidia,enable-input = <0x0>;
			};

			pbb6 {
				nvidia,pins = "pbb6";
				nvidia,pull = <0x0>;
				nvidia,tristate = <0x0>;
				nvidia,enable-input = <0x0>;
			};

			pbb7 {
				nvidia,pins = "pbb7";
				nvidia,pull = <0x0>;
				nvidia,tristate = <0x0>;
				nvidia,enable-input = <0x0>;
			};

			cam_mclk_pcc0 {
				nvidia,pins = "cam_mclk_pcc0";
				nvidia,function = "vi_alt3";
				nvidia,pull = <0x0>;
				nvidia,tristate = <0x0>;
				nvidia,enable-input = <0x0>;
			};

			pcc1 {
				nvidia,pins = "pcc1";
				nvidia,pull = <0x0>;
				nvidia,tristate = <0x0>;
				nvidia,enable-input = <0x1>;
			};

			pcc2 {
				nvidia,pins = "pcc2";
				nvidia,pull = <0x0>;
				nvidia,tristate = <0x0>;
				nvidia,enable-input = <0x1>;
			};

			sdmmc4_clk_pcc4 {
				nvidia,pins = "sdmmc4_clk_pcc4";
				nvidia,function = "sdmmc4";
				nvidia,pull = <0x0>;
				nvidia,tristate = <0x0>;
				nvidia,enable-input = <0x1>;
			};

			clk2_req_pcc5 {
				nvidia,pins = "clk2_req_pcc5";
				nvidia,function = "rsvd2";
				nvidia,pull = <0x1>;
				nvidia,tristate = <0x1>;
				nvidia,enable-input = <0x0>;
			};

			pex_l0_rst_n_pdd1 {
				nvidia,pins = "pex_l0_rst_n_pdd1";
				nvidia,function = "pe0";
				nvidia,pull = <0x0>;
				nvidia,tristate = <0x0>;
				nvidia,enable-input = <0x0>;
			};

			pex_l0_clkreq_n_pdd2 {
				nvidia,pins = "pex_l0_clkreq_n_pdd2";
				nvidia,function = "pe0";
				nvidia,pull = <0x0>;
				nvidia,tristate = <0x1>;
				nvidia,enable-input = <0x1>;
			};

			pex_wake_n_pdd3 {
				nvidia,pins = "pex_wake_n_pdd3";
				nvidia,function = "pe";
				nvidia,pull = <0x0>;
				nvidia,tristate = <0x1>;
				nvidia,enable-input = <0x1>;
			};

			pex_l1_rst_n_pdd5 {
				nvidia,pins = "pex_l1_rst_n_pdd5";
				nvidia,function = "pe1";
				nvidia,pull = <0x0>;
				nvidia,tristate = <0x0>;
				nvidia,enable-input = <0x0>;
			};

			pex_l1_clkreq_n_pdd6 {
				nvidia,pins = "pex_l1_clkreq_n_pdd6";
				nvidia,function = "pe1";
				nvidia,pull = <0x0>;
				nvidia,tristate = <0x1>;
				nvidia,enable-input = <0x1>;
			};

			clk3_out_pee0 {
				nvidia,pins = "clk3_out_pee0";
				nvidia,function = "extperiph3";
				nvidia,pull = <0x0>;
				nvidia,tristate = <0x0>;
				nvidia,enable-input = <0x0>;
			};

			clk3_req_pee1 {
				nvidia,pins = "clk3_req_pee1";
				nvidia,function = "rsvd2";
				nvidia,pull = <0x1>;
				nvidia,tristate = <0x1>;
				nvidia,enable-input = <0x0>;
			};

			dap_mclk1_req_pee2 {
				nvidia,pins = "dap_mclk1_req_pee2";
				nvidia,pull = <0x0>;
				nvidia,tristate = <0x0>;
				nvidia,enable-input = <0x0>;
			};

			hdmi_cec_pee3 {
				nvidia,pins = "hdmi_cec_pee3";
				nvidia,function = "cec";
				nvidia,pull = <0x0>;
				nvidia,tristate = <0x0>;
				nvidia,enable-input = <0x1>;
				nvidia,open-drain = <0x0>;
			};

			sdmmc3_clk_lb_out_pee4 {
				nvidia,pins = "sdmmc3_clk_lb_out_pee4";
				nvidia,function = "sdmmc3";
				nvidia,pull = <0x2>;
				nvidia,tristate = <0x0>;
				nvidia,enable-input = <0x1>;
			};

			sdmmc3_clk_lb_in_pee5 {
				nvidia,pins = "sdmmc3_clk_lb_in_pee5";
				nvidia,function = "sdmmc3";
				nvidia,pull = <0x2>;
				nvidia,tristate = <0x0>;
				nvidia,enable-input = <0x1>;
			};

			dp_hpd_pff0 {
				nvidia,pins = "dp_hpd_pff0";
				nvidia,function = "dp";
				nvidia,pull = <0x0>;
				nvidia,tristate = <0x1>;
				nvidia,enable-input = <0x1>;
			};

			usb_vbus_en2_pff1 {
				nvidia,pins = "usb_vbus_en2_pff1";
				nvidia,function = "rsvd2";
				nvidia,pull = <0x1>;
				nvidia,tristate = <0x1>;
				nvidia,enable-input = <0x0>;
				nvidia,open-drain = <0x0>;
			};

			pff2 {
				nvidia,pins = "pff2";
				nvidia,function = "rsvd2";
				nvidia,pull = <0x1>;
				nvidia,tristate = <0x1>;
				nvidia,enable-input = <0x0>;
				nvidia,open-drain = <0x0>;
			};

			core_pwr_req {
				nvidia,pins = "core_pwr_req";
				nvidia,function = "pwron";
				nvidia,pull = <0x0>;
				nvidia,tristate = <0x0>;
				nvidia,enable-input = <0x0>;
			};

			cpu_pwr_req {
				nvidia,pins = "cpu_pwr_req";
				nvidia,function = "cpu";
				nvidia,pull = <0x0>;
				nvidia,tristate = <0x0>;
				nvidia,enable-input = <0x0>;
			};

			pwr_int_n {
				nvidia,pins = "pwr_int_n";
				nvidia,function = "pmi";
				nvidia,pull = <0x2>;
				nvidia,tristate = <0x1>;
				nvidia,enable-input = <0x1>;
			};

			reset_out_n {
				nvidia,pins = "reset_out_n";
				nvidia,function = "reset_out_n";
				nvidia,pull = <0x0>;
				nvidia,tristate = <0x0>;
				nvidia,enable-input = <0x1>;
			};

			owr {
				nvidia,pins = "owr";
				nvidia,function = "rsvd2";
				nvidia,pull = <0x1>;
				nvidia,tristate = <0x1>;
				nvidia,enable-input = <0x0>;
				nvidia,rcv-sel = <0x0>;
			};

			clk_32k_in {
				nvidia,pins = "clk_32k_in";
				nvidia,function = "clk";
				nvidia,pull = <0x0>;
				nvidia,tristate = <0x1>;
				nvidia,enable-input = <0x1>;
			};

			jtag_rtck {
				nvidia,pins = "jtag_rtck";
				nvidia,function = "rtck";
				nvidia,pull = <0x2>;
				nvidia,tristate = <0x0>;
				nvidia,enable-input = <0x0>;
			};
		};
	};

	serial@0,70006000 {
		compatible = "nvidia,tegra124-uart", "nvidia,tegra20-uart";
		reg = <0x0 0x70006000 0x0 0x40>;
		reg-shift = <0x2>;
		interrupts = <0x0 0x24 0x4>;
		clocks = <0x2 0x6>;
		resets = <0x2 0x6>;
		reset-names = "serial";
		dmas = <0x10 0x8 0x10 0x8>;
		dma-names = "rx", "tx";
		status = "disabled";
	};

	serial@0,70006040 {
		compatible = "nvidia,tegra124-uart", "nvidia,tegra20-uart";
		reg = <0x0 0x70006040 0x0 0x40>;
		reg-shift = <0x2>;
		interrupts = <0x0 0x25 0x4>;
		clocks = <0x2 0xc0>;
		resets = <0x2 0x7>;
		reset-names = "serial";
		dmas = <0x10 0x9 0x10 0x9>;
		dma-names = "rx", "tx";
		status = "disabled";
	};

	serial@0,70006200 {
		compatible = "nvidia,tegra124-uart", "nvidia,tegra20-uart";
		reg = <0x0 0x70006200 0x0 0x40>;
		reg-shift = <0x2>;
		interrupts = <0x0 0x2e 0x4>;
		clocks = <0x2 0x37>;
		resets = <0x2 0x37>;
		reset-names = "serial";
		dmas = <0x10 0xa 0x10 0xa>;
		dma-names = "rx", "tx";
		status = "disabled";
	};

	serial@0,70006300 {
		compatible = "nvidia,tegra124-uart", "nvidia,tegra20-uart";
		reg = <0x0 0x70006300 0x0 0x40>;
		reg-shift = <0x2>;
		interrupts = <0x0 0x5a 0x4>;
		clocks = <0x2 0x41>;
		resets = <0x2 0x41>;
		reset-names = "serial";
		dmas = <0x10 0x13 0x10 0x13>;
		dma-names = "rx", "tx";
		status = "okay";
	};

	pwm@0,7000a000 {
		compatible = "nvidia,tegra124-pwm", "nvidia,tegra20-pwm";
		reg = <0x0 0x7000a000 0x0 0x100>;
		#pwm-cells = <0x2>;
		clocks = <0x2 0x11>;
		resets = <0x2 0x11>;
		reset-names = "pwm";
		status = "disabled";
	};

	i2c@0,7000c000 {
		compatible = "nvidia,tegra124-i2c", "nvidia,tegra114-i2c";
		reg = <0x0 0x7000c000 0x0 0x100>;
		interrupts = <0x0 0x26 0x4>;
		#address-cells = <0x1>;
		#size-cells = <0x0>;
		clocks = <0x2 0xc>;
		clock-names = "div-clk";
		resets = <0x2 0xc>;
		reset-names = "i2c";
		dmas = <0x10 0x15 0x10 0x15>;
		dma-names = "rx", "tx";
		status = "okay";
		clock-frequency = <0x186a0>;

		audio-codec@1c {
			compatible = "realtek,rt5639";
			reg = <0x1c>;
			interrupt-parent = <0xc>;
			interrupts = <0x3c 0x0>;
			realtek,ldo1-en-gpios = <0xc 0x8a 0x0>;
			linux,phandle = <0x2a>;
			phandle = <0x2a>;
		};

		temperature-sensor@4c {
			compatible = "ti,tmp451";
			reg = <0x4c>;
			interrupt-parent = <0xc>;
			interrupts = <0x46 0x8>;
		};
	};

	i2c@0,7000c400 {
		compatible = "nvidia,tegra124-i2c", "nvidia,tegra114-i2c";
		reg = <0x0 0x7000c400 0x0 0x100>;
		interrupts = <0x0 0x54 0x4>;
		#address-cells = <0x1>;
		#size-cells = <0x0>;
		clocks = <0x2 0x36>;
		clock-names = "div-clk";
		resets = <0x2 0x36>;
		reset-names = "i2c";
		dmas = <0x10 0x16 0x10 0x16>;
		dma-names = "rx", "tx";
		status = "okay";
		clock-frequency = <0x186a0>;
	};

	i2c@0,7000c500 {
		compatible = "nvidia,tegra124-i2c", "nvidia,tegra114-i2c";
		reg = <0x0 0x7000c500 0x0 0x100>;
		interrupts = <0x0 0x5c 0x4>;
		#address-cells = <0x1>;
		#size-cells = <0x0>;
		clocks = <0x2 0x43>;
		clock-names = "div-clk";
		resets = <0x2 0x43>;
		reset-names = "i2c";
		dmas = <0x10 0x17 0x10 0x17>;
		dma-names = "rx", "tx";
		status = "okay";
		clock-frequency = <0x186a0>;
	};

	i2c@0,7000c700 {
		compatible = "nvidia,tegra124-i2c", "nvidia,tegra114-i2c";
		reg = <0x0 0x7000c700 0x0 0x100>;
		interrupts = <0x0 0x78 0x4>;
		#address-cells = <0x1>;
		#size-cells = <0x0>;
		clocks = <0x2 0x67>;
		clock-names = "div-clk";
		resets = <0x2 0x67>;
		reset-names = "i2c";
		dmas = <0x10 0x1a 0x10 0x1a>;
		dma-names = "rx", "tx";
		status = "okay";
		clock-frequency = <0x186a0>;
		linux,phandle = <0xb>;
		phandle = <0xb>;
	};

	i2c@0,7000d000 {
		compatible = "nvidia,tegra124-i2c", "nvidia,tegra114-i2c";
		reg = <0x0 0x7000d000 0x0 0x100>;
		interrupts = <0x0 0x35 0x4>;
		#address-cells = <0x1>;
		#size-cells = <0x0>;
		clocks = <0x2 0x2f>;
		clock-names = "div-clk";
		resets = <0x2 0x2f>;
		reset-names = "i2c";
		dmas = <0x10 0x18 0x10 0x18>;
		dma-names = "rx", "tx";
		status = "okay";
		clock-frequency = <0x61a80>;

		pmic@40 {
			compatible = "ams,as3722";
			reg = <0x40>;
			interrupts = <0x0 0x56 0x4>;
			ams,system-power-controller;
			#interrupt-cells = <0x2>;
			interrupt-controller;
			gpio-controller;
			#gpio-cells = <0x2>;
			pinctrl-names = "default";
			pinctrl-0 = <0x11>;
			linux,phandle = <0x28>;
			phandle = <0x28>;

			pinmux {
				linux,phandle = <0x11>;
				phandle = <0x11>;

				gpio0 {
					pins = "gpio0";
					function = "gpio";
					bias-pull-down;
				};

				gpio1_2_4_7 {
					pins = "gpio1", "gpio2", "gpio4", "gpio7";
					function = "gpio";
					bias-pull-up;
				};

				gpio3_5_6 {
					pins = "gpio3", "gpio5", "gpio6";
					bias-high-impedance;
				};
			};

			regulators {
				vsup-sd2-supply = <0x12>;
				vsup-sd3-supply = <0x12>;
				vsup-sd4-supply = <0x12>;
				vsup-sd5-supply = <0x12>;
				vin-ldo0-supply = <0x13>;
				vin-ldo1-6-supply = <0x14>;
				vin-ldo2-5-7-supply = <0x15>;
				vin-ldo3-4-supply = <0x16>;
				vin-ldo9-10-supply = <0x12>;
				vin-ldo11-supply = <0x14>;

				sd0 {
					regulator-name = "+VDD_CPU_AP";
					regulator-min-microvolt = <0xaae60>;
					regulator-max-microvolt = <0x155cc0>;
					regulator-min-microamp = <0x3567e0>;
					regulator-max-microamp = <0x3567e0>;
					regulator-always-on;
					regulator-boot-on;
					ams,ext-control = <0x2>;
					linux,phandle = <0x1c>;
					phandle = <0x1c>;
				};

				sd1 {
					regulator-name = "+VDD_CORE";
					regulator-min-microvolt = <0xaae60>;
					regulator-max-microvolt = <0x149970>;
					regulator-min-microamp = <0x2625a0>;
					regulator-max-microamp = <0x2625a0>;
					regulator-always-on;
					regulator-boot-on;
					ams,ext-control = <0x1>;
				};

				sd2 {
					regulator-name = "+1.35V_LP0(sd2)";
					regulator-min-microvolt = <0x149970>;
					regulator-max-microvolt = <0x149970>;
					regulator-always-on;
					regulator-boot-on;
					linux,phandle = <0x13>;
					phandle = <0x13>;
				};

				sd3 {
					regulator-name = "+1.35V_LP0(sd3)";
					regulator-min-microvolt = <0x149970>;
					regulator-max-microvolt = <0x149970>;
					regulator-always-on;
					regulator-boot-on;
				};

				sd4 {
					regulator-name = "+1.05V_RUN";
					regulator-min-microvolt = <0x100590>;
					regulator-max-microvolt = <0x100590>;
					linux,phandle = <0x4>;
					phandle = <0x4>;
				};

				sd5 {
					regulator-name = "+1.8V_VDDIO";
					regulator-min-microvolt = <0x1b7740>;
					regulator-max-microvolt = <0x1b7740>;
					regulator-boot-on;
					regulator-always-on;
					linux,phandle = <0x15>;
					phandle = <0x15>;
				};

				sd6 {
					regulator-name = "+VDD_GPU_AP";
					regulator-min-microvolt = <0x9eb10>;
					regulator-max-microvolt = <0x124f80>;
					regulator-min-microamp = <0x3567e0>;
					regulator-max-microamp = <0x3567e0>;
					regulator-boot-on;
					regulator-always-on;
				};

				ldo0 {
					regulator-name = "+1.05V_RUN_AVDD";
					regulator-min-microvolt = <0x100590>;
					regulator-max-microvolt = <0x100590>;
					regulator-boot-on;
					regulator-always-on;
					ams,ext-control = <0x1>;
					linux,phandle = <0x6>;
					phandle = <0x6>;
				};

				ldo1 {
					regulator-name = "+1.8V_RUN_CAM";
					regulator-min-microvolt = <0x1b7740>;
					regulator-max-microvolt = <0x1b7740>;
				};

				ldo2 {
					regulator-name = "+1.2V_GEN_AVDD";
					regulator-min-microvolt = <0x124f80>;
					regulator-max-microvolt = <0x124f80>;
					regulator-boot-on;
					regulator-always-on;
				};

				ldo3 {
					regulator-name = "+1.05V_LP0_VDD_RTC";
					regulator-min-microvolt = <0xf4240>;
					regulator-max-microvolt = <0xf4240>;
					regulator-boot-on;
					regulator-always-on;
					ams,enable-tracking;
				};

				ldo4 {
					regulator-name = "+2.8V_RUN_CAM";
					regulator-min-microvolt = <0x2ab980>;
					regulator-max-microvolt = <0x2ab980>;
				};

				ldo5 {
					regulator-name = "+1.2V_RUN_CAM_FRONT";
					regulator-min-microvolt = <0x124f80>;
					regulator-max-microvolt = <0x124f80>;
				};

				ldo6 {
					regulator-name = "+VDDIO_SDMMC3";
					regulator-min-microvolt = <0x1b7740>;
					regulator-max-microvolt = <0x325aa0>;
					linux,phandle = <0x1b>;
					phandle = <0x1b>;
				};

				ldo7 {
					regulator-name = "+1.05V_RUN_CAM_REAR";
					regulator-min-microvolt = <0x100590>;
					regulator-max-microvolt = <0x100590>;
				};

				ldo9 {
					regulator-name = "+3.3V_RUN_TOUCH";
					regulator-min-microvolt = <0x2ab980>;
					regulator-max-microvolt = <0x2ab980>;
				};

				ldo10 {
					regulator-name = "+2.8V_RUN_CAM_AF";
					regulator-min-microvolt = <0x2ab980>;
					regulator-max-microvolt = <0x2ab980>;
				};

				ldo11 {
					regulator-name = "+1.8V_RUN_VPP_FUSE";
					regulator-min-microvolt = <0x1b7740>;
					regulator-max-microvolt = <0x1b7740>;
				};
			};
		};
	};

	i2c@0,7000d100 {
		compatible = "nvidia,tegra124-i2c", "nvidia,tegra114-i2c";
		reg = <0x0 0x7000d100 0x0 0x100>;
		interrupts = <0x0 0x3f 0x4>;
		#address-cells = <0x1>;
		#size-cells = <0x0>;
		clocks = <0x2 0xa6>;
		clock-names = "div-clk";
		resets = <0x2 0xa6>;
		reset-names = "i2c";
		dmas = <0x10 0x1e 0x10 0x1e>;
		dma-names = "rx", "tx";
		status = "disabled";
	};

	spi@0,7000d400 {
		compatible = "nvidia,tegra124-spi", "nvidia,tegra114-spi";
		reg = <0x0 0x7000d400 0x0 0x200>;
		interrupts = <0x0 0x3b 0x4>;
		#address-cells = <0x1>;
		#size-cells = <0x0>;
		clocks = <0x2 0x29>;
		clock-names = "spi";
		resets = <0x2 0x29>;
		reset-names = "spi";
		dmas = <0x10 0xf 0x10 0xf>;
		dma-names = "rx", "tx";
		status = "okay";
	};

	spi@0,7000d600 {
		compatible = "nvidia,tegra124-spi", "nvidia,tegra114-spi";
		reg = <0x0 0x7000d600 0x0 0x200>;
		interrupts = <0x0 0x52 0x4>;
		#address-cells = <0x1>;
		#size-cells = <0x0>;
		clocks = <0x2 0x2c>;
		clock-names = "spi";
		resets = <0x2 0x2c>;
		reset-names = "spi";
		dmas = <0x10 0x10 0x10 0x10>;
		dma-names = "rx", "tx";
		status = "disabled";
	};

	spi@0,7000d800 {
		compatible = "nvidia,tegra124-spi", "nvidia,tegra114-spi";
		reg = <0x0 0x7000d800 0x0 0x200>;
		interrupts = <0x0 0x53 0x4>;
		#address-cells = <0x1>;
		#size-cells = <0x0>;
		clocks = <0x2 0x2e>;
		clock-names = "spi";
		resets = <0x2 0x2e>;
		reset-names = "spi";
		dmas = <0x10 0x11 0x10 0x11>;
		dma-names = "rx", "tx";
		status = "disabled";
	};

	spi@0,7000da00 {
		compatible = "nvidia,tegra124-spi", "nvidia,tegra114-spi";
		reg = <0x0 0x7000da00 0x0 0x200>;
		interrupts = <0x0 0x5d 0x4>;
		#address-cells = <0x1>;
		#size-cells = <0x0>;
		clocks = <0x2 0x44>;
		clock-names = "spi";
		resets = <0x2 0x44>;
		reset-names = "spi";
		dmas = <0x10 0x12 0x10 0x12>;
		dma-names = "rx", "tx";
		status = "okay";
		spi-max-frequency = <0x17d7840>;

		spi-flash@0 {
			compatible = "winbond,w25q32dw";
			reg = <0x0>;
			spi-max-frequency = <0x1312d00>;
		};
	};

	spi@0,7000dc00 {
		compatible = "nvidia,tegra124-spi", "nvidia,tegra114-spi";
		reg = <0x0 0x7000dc00 0x0 0x200>;
		interrupts = <0x0 0x5e 0x4>;
		#address-cells = <0x1>;
		#size-cells = <0x0>;
		clocks = <0x2 0x68>;
		clock-names = "spi";
		resets = <0x2 0x68>;
		reset-names = "spi";
		dmas = <0x10 0x1b 0x10 0x1b>;
		dma-names = "rx", "tx";
		status = "disabled";
	};

	spi@0,7000de00 {
		compatible = "nvidia,tegra124-spi", "nvidia,tegra114-spi";
		reg = <0x0 0x7000de00 0x0 0x200>;
		interrupts = <0x0 0x4f 0x4>;
		#address-cells = <0x1>;
		#size-cells = <0x0>;
		clocks = <0x2 0x69>;
		clock-names = "spi";
		resets = <0x2 0x69>;
		reset-names = "spi";
		dmas = <0x10 0x1c 0x10 0x1c>;
		dma-names = "rx", "tx";
		status = "disabled";
	};

	rtc@0,7000e000 {
		compatible = "nvidia,tegra124-rtc", "nvidia,tegra20-rtc";
		reg = <0x0 0x7000e000 0x0 0x100>;
		interrupts = <0x0 0x2 0x4>;
		clocks = <0x2 0x4>;
	};

	pmc@0,7000e400 {
		compatible = "nvidia,tegra124-pmc";
		reg = <0x0 0x7000e400 0x0 0x400>;
		clocks = <0x2 0x105 0x17>;
		clock-names = "pclk", "clk32k_in";
		nvidia,invert-interrupt;
		nvidia,suspend-mode = <0x1>;
		nvidia,cpu-pwr-good-time = <0x1f4>;
		nvidia,cpu-pwr-off-time = <0x12c>;
		nvidia,core-pwr-good-time = <0x281 0xf05>;
		nvidia,core-pwr-off-time = <0xee6c>;
		nvidia,core-power-req-active-high;
		nvidia,sys-clock-req-active-high;

		i2c-thermtrip {
			nvidia,i2c-controller-id = <0x4>;
			nvidia,bus-addr = <0x40>;
			nvidia,reg-addr = <0x36>;
			nvidia,reg-data = <0x2>;
		};
	};

	fuse@0,7000f800 {
		compatible = "nvidia,tegra124-efuse";
		reg = <0x0 0x7000f800 0x0 0x400>;
		clocks = <0x2 0xc6>;
		clock-names = "fuse";
		resets = <0x2 0x27>;
		reset-names = "fuse";
	};

	memory-controller@0,70019000 {
		compatible = "nvidia,tegra124-mc";
		reg = <0x0 0x70019000 0x0 0x1000>;
		clocks = <0x2 0x20>;
		clock-names = "mc";
		interrupts = <0x0 0x4d 0x4>;
		#iommu-cells = <0x1>;
		linux,phandle = <0x7>;
		phandle = <0x7>;

		emc-timings-3 {
			nvidia,ram-code = <0x3>;

			timing-12750000 {
				clock-frequency = <0xc28cb0>;
				nvidia,emem-configuration = <0x40040001 0x8000000a 0x1 0x1 0x2 0x0 0x2 0x1 0x3 0x8 0x3 0x2 0x3 0x6 0x6030203 0xa0502 0x77e30303 0x70000f03 0x1f0000>;
			};

			timing-20400000 {
				clock-frequency = <0x1374780>;
				nvidia,emem-configuration = <0x40020001 0x80000012 0x1 0x1 0x2 0x0 0x2 0x1 0x3 0x8 0x3 0x2 0x3 0x6 0x6030203 0xa0502 0x76230303 0x70000f03 0x1f0000>;
			};

			timing-40800000 {
				clock-frequency = <0x26e8f00>;
				nvidia,emem-configuration = <0xa0000001 0x80000017 0x1 0x1 0x2 0x0 0x2 0x1 0x3 0x8 0x3 0x2 0x3 0x6 0x6030203 0xa0502 0x74a30303 0x70000f03 0x1f0000>;
			};

			timing-68000000 {
				clock-frequency = <0x40d9900>;
				nvidia,emem-configuration = <0x1 0x8000001e 0x1 0x1 0x2 0x0 0x2 0x1 0x3 0x8 0x3 0x2 0x3 0x6 0x6030203 0xa0502 0x74230403 0x70000f03 0x1f0000>;
			};

			timing-102000000 {
				clock-frequency = <0x6146580>;
				nvidia,emem-configuration = <0x8000001 0x80000026 0x1 0x1 0x3 0x0 0x2 0x1 0x3 0x8 0x3 0x2 0x3 0x6 0x6030203 0xa0503 0x73c30504 0x70000f03 0x1f0000>;
			};

			timing-204000000 {
				clock-frequency = <0xc28cb00>;
				nvidia,emem-configuration = <0x1000003 0x80000040 0x1 0x1 0x4 0x2 0x3 0x1 0x3 0x8 0x3 0x2 0x4 0x6 0x6040203 0xa0504 0x73840a05 0x70000f03 0x1f0000>;
			};

			timing-300000000 {
				clock-frequency = <0x11e1a300>;
				nvidia,emem-configuration = <0x8000004 0x80000040 0x1 0x2 0x7 0x4 0x4 0x1 0x2 0x7 0x2 0x2 0x4 0x6 0x6040202 0xb0607 0x77450e08 0x70000f03 0x1f0000>;
			};

			timing-396000000 {
				clock-frequency = <0x179a7b00>;
				nvidia,emem-configuration = <0xf000005 0x80000040 0x1 0x2 0x9 0x5 0x6 0x1 0x2 0x8 0x2 0x2 0x4 0x6 0x6040202 0xd0709 0x7586120a 0x70000f03 0x1f0000>;
			};

			timing-528000000 {
				clock-frequency = <0x1f78a400>;
				nvidia,emem-configuration = <0xf000007 0x80000040 0x2 0x3 0xc 0x7 0x8 0x1 0x2 0x9 0x2 0x2 0x5 0x6 0x6050202 0x10090c 0x7428180d 0x70000f03 0x1f0000>;
			};

			timing-600000000 {
				clock-frequency = <0x23c34600>;
				nvidia,emem-configuration = <0x9 0x80000040 0x3 0x4 0xe 0x9 0xa 0x1 0x3 0xb 0x2 0x2 0x5 0x7 0x7050202 0x130b0e 0x73a91b0f 0x70000f03 0x1f0000>;
			};

			timing-792000000 {
				clock-frequency = <0x2f34f600>;
				nvidia,emem-configuration = <0xe00000b 0x80000040 0x4 0x5 0x13 0xc 0xd 0x2 0x3 0xc 0x2 0x2 0x6 0x8 0x8060202 0x170e13 0x736c2414 0x70000f02 0x1f0000>;
			};

			timing-924000000 {
				clock-frequency = <0x37131f00>;
				nvidia,emem-configuration = <0xe00000d 0x80000040 0x5 0x6 0x16 0xe 0xf 0x2 0x4 0xe 0x2 0x2 0x6 0x9 0x9060202 0x1a1016 0x734e2a17 0x70000f02 0x1f0000>;
			};
		};
	};

	emc@0,7001b000 {
		compatible = "nvidia,tegra124-emc";
		reg = <0x0 0x7001b000 0x0 0x1000>;
		nvidia,memory-controller = <0x7>;
		linux,phandle = <0xd>;
		phandle = <0xd>;

		emc-timings-3 {
			nvidia,ram-code = <0x3>;

			timing-12750000 {
				clock-frequency = <0xc28cb0>;
				nvidia,emc-auto-cal-config = <0xa1430000>;
				nvidia,emc-auto-cal-config2 = <0x0>;
				nvidia,emc-auto-cal-config3 = <0x0>;
				nvidia,emc-auto-cal-interval = <0x1fffff>;
				nvidia,emc-bgbias-ctl0 = <0x8>;
				nvidia,emc-cfg = <0x73240000>;
				nvidia,emc-cfg-2 = <0x8c5>;
				nvidia,emc-ctt-term-ctrl = <0x802>;
				nvidia,emc-mode-1 = <0x80100003>;
				nvidia,emc-mode-2 = <0x80200008>;
				nvidia,emc-mode-4 = <0x0>;
				nvidia,emc-mode-reset = <0x80001221>;
				nvidia,emc-mrs-wait-cnt = <0xe000e>;
				nvidia,emc-sel-dpd-ctrl = <0x40128>;
				nvidia,emc-xm2dqspadctrl2 = <0x130b118>;
				nvidia,emc-zcal-cnt-long = <0x42>;
				nvidia,emc-zcal-interval = <0x0>;
				nvidia,emc-configuration = <0x0 0x3 0x0 0x0 0x0 0x4 0xa 0x5 0xb 0x0 0x0 0x3 0x3 0x0 0x6 0x6 0x6 0x2 0x0 0x5 0x5 0x10000 0x3 0x0 0x0 0x0 0x0 0x4 0xc 0xd 0xf 0x60 0x0 0x18 0x2 0x2 0x1 0x0 0x7 0xf 0x5 0x5 0x4 0x5 0x4 0x0 0x0 0x5 0x5 0x64 0x0 0x0 0x0 0x106aa298 0x2c00a0 0x8000 0x80000 0x80000 0x80000 0x80000 0x80000 0x80000 0x80000 0x80000 0x80000 0x80000 0x80000 0x80000 0x80000 0x80000 0x80000 0x80000 0x0 0x0 0x0 0x0 0x0 0x0 0x0 0x0 0x0 0x0 0x0 0x0 0x0 0x0 0x0 0x0 0x0 0x0 0x0 0x0 0x0 0x0 0x0 0x0 0x0 0x0 0x0 0x0 0x0 0x0 0x0 0x0 0x0 0x0 0x0 0x0 0x0 0x0 0xfc000 0xfc000 0xfc000 0xfc000 0xfc00 0xfc00 0xfc00 0xfc00 0x10000280 0x0 0x111111 0x0 0x0 0x77ffc081 0xe0e 0x81f1f108 0x7070004 0x3f 0x16eeeee 0x51451400 0x514514 0x514514 0x51451400 0x3f 0x7 0x0 0x42 0xe000e 0x0 0x3 0xf2f3 0x800001c5 0xa>;
			};

			timing-20400000 {
				clock-frequency = <0x1374780>;
				nvidia,emc-auto-cal-config = <0xa1430000>;
				nvidia,emc-auto-cal-config2 = <0x0>;
				nvidia,emc-auto-cal-config3 = <0x0>;
				nvidia,emc-auto-cal-interval = <0x1fffff>;
				nvidia,emc-bgbias-ctl0 = <0x8>;
				nvidia,emc-cfg = <0x73240000>;
				nvidia,emc-cfg-2 = <0x8c5>;
				nvidia,emc-ctt-term-ctrl = <0x802>;
				nvidia,emc-mode-1 = <0x80100003>;
				nvidia,emc-mode-2 = <0x80200008>;
				nvidia,emc-mode-4 = <0x0>;
				nvidia,emc-mode-reset = <0x80001221>;
				nvidia,emc-mrs-wait-cnt = <0xe000e>;
				nvidia,emc-sel-dpd-ctrl = <0x40128>;
				nvidia,emc-xm2dqspadctrl2 = <0x130b118>;
				nvidia,emc-zcal-cnt-long = <0x42>;
				nvidia,emc-zcal-interval = <0x0>;
				nvidia,emc-configuration = <0x0 0x5 0x0 0x0 0x0 0x4 0xa 0x5 0xb 0x0 0x0 0x3 0x3 0x0 0x6 0x6 0x6 0x2 0x0 0x5 0x5 0x10000 0x3 0x0 0x0 0x0 0x0 0x4 0xc 0xd 0xf 0x9a 0x0 0x26 0x2 0x2 0x1 0x0 0x7 0xf 0x6 0x6 0x4 0x5 0x4 0x0 0x0 0x5 0x5 0xa0 0x0 0x0 0x0 0x106aa298 0x2c00a0 0x8000 0x80000 0x80000 0x80000 0x80000 0x80000 0x80000 0x80000 0x80000 0x80000 0x80000 0x80000 0x80000 0x80000 0x80000 0x80000 0x80000 0x0 0x0 0x0 0x0 0x0 0x0 0x0 0x0 0x0 0x0 0x0 0x0 0x0 0x0 0x0 0x0 0x0 0x0 0x0 0x0 0x0 0x0 0x0 0x0 0x0 0x0 0x0 0x0 0x0 0x0 0x0 0x0 0x0 0x0 0x0 0x0 0x0 0x0 0xfc000 0xfc000 0xfc000 0xfc000 0xfc00 0xfc00 0xfc00 0xfc00 0x10000280 0x0 0x111111 0x0 0x0 0x77ffc081 0xe0e 0x81f1f108 0x7070004 0x3f 0x16eeeee 0x51451400 0x514514 0x514514 0x51451400 0x3f 0xb 0x0 0x42 0xe000e 0x0 0x3 0xf2f3 0x8000023a 0xa>;
			};

			timing-40800000 {
				clock-frequency = <0x26e8f00>;
				nvidia,emc-auto-cal-config = <0xa1430000>;
				nvidia,emc-auto-cal-config2 = <0x0>;
				nvidia,emc-auto-cal-config3 = <0x0>;
				nvidia,emc-auto-cal-interval = <0x1fffff>;
				nvidia,emc-bgbias-ctl0 = <0x8>;
				nvidia,emc-cfg = <0x73240000>;
				nvidia,emc-cfg-2 = <0x8c5>;
				nvidia,emc-ctt-term-ctrl = <0x802>;
				nvidia,emc-mode-1 = <0x80100003>;
				nvidia,emc-mode-2 = <0x80200008>;
				nvidia,emc-mode-4 = <0x0>;
				nvidia,emc-mode-reset = <0x80001221>;
				nvidia,emc-mrs-wait-cnt = <0xe000e>;
				nvidia,emc-sel-dpd-ctrl = <0x40128>;
				nvidia,emc-xm2dqspadctrl2 = <0x130b118>;
				nvidia,emc-zcal-cnt-long = <0x42>;
				nvidia,emc-zcal-interval = <0x0>;
				nvidia,emc-configuration = <0x1 0xa 0x0 0x1 0x0 0x4 0xa 0x5 0xb 0x0 0x0 0x3 0x3 0x0 0x6 0x6 0x6 0x2 0x0 0x5 0x5 0x10000 0x3 0x0 0x0 0x0 0x0 0x4 0xc 0xd 0xf 0x134 0x0 0x4d 0x2 0x2 0x1 0x0 0x8 0xf 0xc 0xc 0x4 0x5 0x4 0x0 0x0 0x5 0x5 0x13f 0x0 0x0 0x0 0x106aa298 0x2c00a0 0x8000 0x80000 0x80000 0x80000 0x80000 0x80000 0x80000 0x80000 0x80000 0x80000 0x80000 0x80000 0x80000 0x80000 0x80000 0x80000 0x80000 0x0 0x0 0x0 0x0 0x0 0x0 0x0 0x0 0x0 0x0 0x0 0x0 0x0 0x0 0x0 0x0 0x0 0x0 0x0 0x0 0x0 0x0 0x0 0x0 0x0 0x0 0x0 0x0 0x0 0x0 0x0 0x0 0x0 0x0 0x0 0x0 0x0 0x0 0xfc000 0xfc000 0xfc000 0xfc000 0xfc00 0xfc00 0xfc00 0xfc00 0x10000280 0x0 0x111111 0x0 0x0 0x77ffc081 0xe0e 0x81f1f108 0x7070004 0x3f 0x16eeeee 0x51451400 0x514514 0x514514 0x51451400 0x3f 0x15 0x0 0x42 0xe000e 0x0 0x3 0xf2f3 0x80000370 0xa>;
			};

			timing-68000000 {
				clock-frequency = <0x40d9900>;
				nvidia,emc-auto-cal-config = <0xa1430000>;
				nvidia,emc-auto-cal-config2 = <0x0>;
				nvidia,emc-auto-cal-config3 = <0x0>;
				nvidia,emc-auto-cal-interval = <0x1fffff>;
				nvidia,emc-bgbias-ctl0 = <0x8>;
				nvidia,emc-cfg = <0x73240000>;
				nvidia,emc-cfg-2 = <0x8c5>;
				nvidia,emc-ctt-term-ctrl = <0x802>;
				nvidia,emc-mode-1 = <0x80100003>;
				nvidia,emc-mode-2 = <0x80200008>;
				nvidia,emc-mode-4 = <0x0>;
				nvidia,emc-mode-reset = <0x80001221>;
				nvidia,emc-mrs-wait-cnt = <0xe000e>;
				nvidia,emc-sel-dpd-ctrl = <0x40128>;
				nvidia,emc-xm2dqspadctrl2 = <0x130b118>;
				nvidia,emc-zcal-cnt-long = <0x42>;
				nvidia,emc-zcal-interval = <0x0>;
				nvidia,emc-configuration = <0x3 0x11 0x0 0x2 0x0 0x4 0xa 0x5 0xb 0x0 0x0 0x3 0x3 0x0 0x6 0x6 0x6 0x2 0x0 0x5 0x5 0x10000 0x3 0x0 0x0 0x0 0x0 0x4 0xc 0xd 0xf 0x202 0x0 0x80 0x2 0x2 0x1 0x0 0xf 0xf 0x13 0x13 0x4 0x5 0x4 0x1 0x0 0x5 0x5 0x213 0x0 0x0 0x0 0x106aa298 0x2c00a0 0x8000 0x80000 0x80000 0x80000 0x80000 0x80000 0x80000 0x80000 0x80000 0x80000 0x80000 0x80000 0x80000 0x80000 0x80000 0x80000 0x80000 0x0 0x0 0x0 0x0 0x0 0x0 0x0 0x0 0x0 0x0 0x0 0x0 0x0 0x0 0x0 0x0 0x0 0x0 0x0 0x0 0x0 0x0 0x0 0x0 0x0 0x0 0x0 0x0 0x0 0x0 0x0 0x0 0x0 0x0 0x0 0x0 0x0 0x0 0xfc000 0xfc000 0xfc000 0xfc000 0xfc00 0xfc00 0xfc00 0xfc00 0x10000280 0x0 0x111111 0x0 0x0 0x77ffc081 0xe0e 0x81f1f108 0x7070004 0x3f 0x16eeeee 0x51451400 0x514514 0x514514 0x51451400 0x3f 0x22 0x0 0x42 0xe000e 0x0 0x3 0xf2f3 0x8000050e 0xa>;
			};

			timing-102000000 {
				clock-frequency = <0x6146580>;
				nvidia,emc-auto-cal-config = <0xa1430000>;
				nvidia,emc-auto-cal-config2 = <0x0>;
				nvidia,emc-auto-cal-config3 = <0x0>;
				nvidia,emc-auto-cal-interval = <0x1fffff>;
				nvidia,emc-bgbias-ctl0 = <0x8>;
				nvidia,emc-cfg = <0x73240000>;
				nvidia,emc-cfg-2 = <0x8c5>;
				nvidia,emc-ctt-term-ctrl = <0x802>;
				nvidia,emc-mode-1 = <0x80100003>;
				nvidia,emc-mode-2 = <0x80200008>;
				nvidia,emc-mode-4 = <0x0>;
				nvidia,emc-mode-reset = <0x80001221>;
				nvidia,emc-mrs-wait-cnt = <0xe000e>;
				nvidia,emc-sel-dpd-ctrl = <0x40128>;
				nvidia,emc-xm2dqspadctrl2 = <0x130b118>;
				nvidia,emc-zcal-cnt-long = <0x42>;
				nvidia,emc-zcal-interval = <0x0>;
				nvidia,emc-configuration = <0x4 0x1a 0x0 0x3 0x1 0x4 0xa 0x5 0xb 0x1 0x1 0x3 0x3 0x0 0x6 0x6 0x6 0x2 0x0 0x5 0x5 0x10000 0x3 0x0 0x0 0x0 0x0 0x4 0xc 0xd 0xf 0x304 0x0 0xc1 0x2 0x2 0x1 0x0 0x18 0xf 0x1c 0x1c 0x4 0x5 0x4 0x2 0x0 0x5 0x5 0x31c 0x0 0x0 0x0 0x106aa298 0x2c00a0 0x8000 0x80000 0x80000 0x80000 0x80000 0x80000 0x80000 0x80000 0x80000 0x80000 0x80000 0x80000 0x80000 0x80000 0x80000 0x80000 0x80000 0x0 0x0 0x0 0x0 0x0 0x0 0x0 0x0 0x0 0x0 0x0 0x0 0x0 0x0 0x0 0x0 0x0 0x0 0x0 0x0 0x0 0x0 0x0 0x0 0x0 0x0 0x0 0x0 0x0 0x0 0x0 0x0 0x0 0x0 0x0 0x0 0x0 0x0 0xfc000 0xfc000 0xfc000 0xfc000 0xfc00 0xfc00 0xfc00 0xfc00 0x10000280 0x0 0x111111 0x0 0x0 0x77ffc081 0xe0e 0x81f1f108 0x7070004 0x3f 0x16eeeee 0x51451400 0x514514 0x514514 0x51451400 0x3f 0x33 0x0 0x42 0xe000e 0x0 0x3 0xf2f3 0x80000713 0xa>;
			};

			timing-204000000 {
				clock-frequency = <0xc28cb00>;
				nvidia,emc-auto-cal-config = <0xa1430000>;
				nvidia,emc-auto-cal-config2 = <0x0>;
				nvidia,emc-auto-cal-config3 = <0x0>;
				nvidia,emc-auto-cal-interval = <0x1fffff>;
				nvidia,emc-bgbias-ctl0 = <0x8>;
				nvidia,emc-cfg = <0x73240000>;
				nvidia,emc-cfg-2 = <0x8cd>;
				nvidia,emc-ctt-term-ctrl = <0x802>;
				nvidia,emc-mode-1 = <0x80100003>;
				nvidia,emc-mode-2 = <0x80200008>;
				nvidia,emc-mode-4 = <0x0>;
				nvidia,emc-mode-reset = <0x80001221>;
				nvidia,emc-mrs-wait-cnt = <0xe000e>;
				nvidia,emc-sel-dpd-ctrl = <0x40128>;
				nvidia,emc-xm2dqspadctrl2 = <0x130b118>;
				nvidia,emc-zcal-cnt-long = <0x42>;
				nvidia,emc-zcal-interval = <0x20000>;
				nvidia,emc-configuration = <0x9 0x35 0x0 0x6 0x2 0x5 0xa 0x5 0xb 0x2 0x2 0x3 0x3 0x0 0x5 0x5 0x6 0x2 0x0 0x4 0x6 0x10000 0x3 0x0 0x0 0x0 0x0 0x3 0xd 0xf 0x11 0x607 0x0 0x181 0x2 0x2 0x1 0x0 0x32 0xf 0x38 0x38 0x4 0x5 0x4 0x6 0x0 0x5 0x5 0x638 0x0 0x0 0x0 0x106aa298 0x2c00a0 0x8000 0x80000 0x80000 0x80000 0x80000 0x80000 0x80000 0x80000 0x80000 0x80000 0x80000 0x80000 0x80000 0x80000 0x80000 0x80000 0x80000 0x0 0x0 0x0 0x0 0x0 0x0 0x0 0x0 0x0 0x0 0x8000 0x0 0x0 0x8000 0x0 0x0 0x0 0x0 0x0 0x0 0x0 0x0 0x0 0x0 0x0 0x0 0x0 0x0 0x0 0x0 0x0 0x0 0x0 0x0 0x0 0x0 0x0 0x0 0x90000 0x90000 0x90000 0x90000 0x9000 0x9000 0x9000 0x9000 0x10000280 0x0 0x111111 0x0 0x0 0x77ffc081 0x707 0x81f1f108 0x7070004 0x3f 0x16eeeee 0x51451400 0x514514 0x514514 0x51451400 0x3f 0x66 0x0 0x100 0xe000e 0x0 0x3 0xd2b3 0x80000d22 0xa>;
			};

			timing-300000000 {
				clock-frequency = <0x11e1a300>;
				nvidia,emc-auto-cal-config = <0xa1430000>;
				nvidia,emc-auto-cal-config2 = <0x0>;
				nvidia,emc-auto-cal-config3 = <0x0>;
				nvidia,emc-auto-cal-interval = <0x1fffff>;
				nvidia,emc-bgbias-ctl0 = <0x0>;
				nvidia,emc-cfg = <0x73340000>;
				nvidia,emc-cfg-2 = <0x8d5>;
				nvidia,emc-ctt-term-ctrl = <0x802>;
				nvidia,emc-mode-1 = <0x80100002>;
				nvidia,emc-mode-2 = <0x80200000>;
				nvidia,emc-mode-4 = <0x0>;
				nvidia,emc-mode-reset = <0x80000321>;
				nvidia,emc-mrs-wait-cnt = <0x173000e>;
				nvidia,emc-sel-dpd-ctrl = <0x40128>;
				nvidia,emc-xm2dqspadctrl2 = <0x1231339>;
				nvidia,emc-zcal-cnt-long = <0x42>;
				nvidia,emc-zcal-interval = <0x20000>;
				nvidia,emc-configuration = <0xd 0x4d 0x0 0x9 0x3 0x4 0x8 0x2 0x9 0x3 0x3 0x2 0x2 0x0 0x3 0x3 0x5 0x2 0x0 0x2 0x7 0x20000 0x3 0x0 0x0 0x0 0x0 0x1 0xe 0x10 0x12 0x8e4 0x0 0x239 0x1 0x8 0x1 0x0 0x4b 0xe 0x52 0x200 0x4 0x5 0x4 0x8 0x0 0x5 0x5 0x924 0x0 0x0 0x0 0x104ab098 0x2c00a0 0x8000 0x30000 0x30000 0x30000 0x30000 0x30000 0x30000 0x30000 0x30000 0x30000 0x30000 0x30000 0x30000 0x30000 0x30000 0x30000 0x30000 0x0 0x0 0x0 0x0 0x0 0x0 0x0 0x0 0x98000 0x98000 0x0 0x98000 0x98000 0x0 0x0 0x0 0x0 0x0 0x0 0x0 0x0 0x0 0x0 0x0 0x0 0x0 0x0 0x0 0x0 0x0 0x0 0x0 0x0 0x0 0x0 0x0 0x0 0x0 0x50000 0x50000 0x50000 0x50000 0x5000 0x5000 0x5000 0x5000 0x10000280 0x0 0x111111 0x0 0x0 0x77ffc081 0x505 0x81f1f108 0x7070004 0x0 0x16eeeee 0x51451420 0x514514 0x514514 0x51451400 0x3f 0x96 0x0 0x100 0x173000e 0x0 0x3 0x52a3 0x800012d7 0x9>;
			};

			timing-396000000 {
				clock-frequency = <0x179a7b00>;
				nvidia,emc-auto-cal-config = <0xa1430000>;
				nvidia,emc-auto-cal-config2 = <0x0>;
				nvidia,emc-auto-cal-config3 = <0x0>;
				nvidia,emc-auto-cal-interval = <0x1fffff>;
				nvidia,emc-bgbias-ctl0 = <0x0>;
				nvidia,emc-cfg = <0x73340000>;
				nvidia,emc-cfg-2 = <0x895>;
				nvidia,emc-ctt-term-ctrl = <0x802>;
				nvidia,emc-mode-1 = <0x80100002>;
				nvidia,emc-mode-2 = <0x80200000>;
				nvidia,emc-mode-4 = <0x0>;
				nvidia,emc-mode-reset = <0x80000521>;
				nvidia,emc-mrs-wait-cnt = <0x15b000e>;
				nvidia,emc-sel-dpd-ctrl = <0x40008>;
				nvidia,emc-xm2dqspadctrl2 = <0x1231339>;
				nvidia,emc-zcal-cnt-long = <0x42>;
				nvidia,emc-zcal-interval = <0x20000>;
				nvidia,emc-configuration = <0x11 0x66 0x0 0xc 0x4 0x4 0x8 0x2 0xa 0x4 0x4 0x2 0x2 0x0 0x3 0x3 0x5 0x2 0x0 0x1 0x8 0x20000 0x3 0x0 0x0 0x0 0x0 0x0 0xf 0x10 0x12 0xbd1 0x0 0x2f4 0x1 0x8 0x1 0x0 0x63 0xf 0x6c 0x200 0x4 0x5 0x4 0xb 0x0 0x5 0x5 0xc11 0x0 0x0 0x0 0x104ab098 0x2c00a0 0x8000 0x30000 0x30000 0x30000 0x30000 0x30000 0x30000 0x30000 0x30000 0x30000 0x30000 0x30000 0x30000 0x30000 0x30000 0x30000 0x30000 0x0 0x0 0x0 0x0 0x0 0x0 0x0 0x0 0x70000 0x70000 0x0 0x70000 0x70000 0x0 0x0 0x0 0x0 0x0 0x0 0x0 0x0 0x0 0x0 0x0 0x0 0x0 0x0 0x0 0x0 0x0 0x0 0x0 0x0 0x0 0x0 0x0 0x0 0x0 0x38000 0x38000 0x38000 0x38000 0x3800 0x3800 0x3800 0x3800 0x10000280 0x0 0x111111 0x0 0x0 0x77ffc081 0x505 0x81f1f108 0x7070004 0x0 0x16eeeee 0x51451420 0x514514 0x514514 0x51451400 0x3f 0xc6 0x0 0x100 0x15b000e 0x0 0x3 0x52a3 0x8000188b 0x9>;
			};

			timing-528000000 {
				clock-frequency = <0x1f78a400>;
				nvidia,emc-auto-cal-config = <0xa1430000>;
				nvidia,emc-auto-cal-config2 = <0x0>;
				nvidia,emc-auto-cal-config3 = <0x0>;
				nvidia,emc-auto-cal-interval = <0x1fffff>;
				nvidia,emc-bgbias-ctl0 = <0x0>;
				nvidia,emc-cfg = <0x73300000>;
				nvidia,emc-cfg-2 = <0x89d>;
				nvidia,emc-ctt-term-ctrl = <0x802>;
				nvidia,emc-mode-1 = <0x80100002>;
				nvidia,emc-mode-2 = <0x80200008>;
				nvidia,emc-mode-4 = <0x0>;
				nvidia,emc-mode-reset = <0x80000941>;
				nvidia,emc-mrs-wait-cnt = <0x139000e>;
				nvidia,emc-sel-dpd-ctrl = <0x40008>;
				nvidia,emc-xm2dqspadctrl2 = <0x123133d>;
				nvidia,emc-zcal-cnt-long = <0x42>;
				nvidia,emc-zcal-interval = <0x20000>;
				nvidia,emc-configuration = <0x18 0x88 0x0 0x10 0x6 0x6 0x9 0x2 0xd 0x6 0x6 0x2 0x2 0x0 0x3 0x3 0x6 0x2 0x0 0x1 0x9 0x30000 0x3 0x0 0x0 0x0 0x0 0x0 0x10 0x12 0x14 0xfd6 0x0 0x3f5 0x2 0xb 0x1 0x0 0x85 0x12 0x90 0x200 0x4 0x5 0x4 0x10 0x0 0x6 0x6 0x1017 0x0 0x0 0x0 0x104ab098 0xe01200b1 0x8000 0xa 0xa 0xa 0xa 0xa 0xa 0xa 0xa 0xa 0xa 0xa 0xa 0xa 0xa 0xa 0xa 0x0 0x0 0x0 0x0 0x0 0x0 0x0 0x0 0x54000 0x54000 0x0 0x54000 0x54000 0x0 0x0 0x0 0x0 0x0 0x0 0x0 0x0 0x0 0x0 0x0 0x0 0x0 0x0 0x0 0x0 0x0 0x0 0x0 0x0 0x0 0x0 0x0 0x0 0x0 0xc 0xc 0xc 0xc 0xc 0xc 0xc 0xc 0x100002a0 0x0 0x111111 0x0 0x0 0x77ffc085 0x505 0x81f1f108 0x7070004 0x0 0x16eeeee 0x51451420 0x514514 0x514514 0x51451400 0x606003f 0x0 0x0 0x100 0x139000e 0x0 0x3 0x42a0 0x80002062 0xa>;
			};

			timing-600000000 {
				clock-frequency = <0x23c34600>;
				nvidia,emc-auto-cal-config = <0xa1430000>;
				nvidia,emc-auto-cal-config2 = <0x0>;
				nvidia,emc-auto-cal-config3 = <0x0>;
				nvidia,emc-auto-cal-interval = <0x1fffff>;
				nvidia,emc-bgbias-ctl0 = <0x0>;
				nvidia,emc-cfg = <0x73300000>;
				nvidia,emc-cfg-2 = <0x89d>;
				nvidia,emc-ctt-term-ctrl = <0x802>;
				nvidia,emc-mode-1 = <0x80100002>;
				nvidia,emc-mode-2 = <0x80200010>;
				nvidia,emc-mode-4 = <0x0>;
				nvidia,emc-mode-reset = <0x80000b61>;
				nvidia,emc-mrs-wait-cnt = <0x127000e>;
				nvidia,emc-sel-dpd-ctrl = <0x40008>;
				nvidia,emc-xm2dqspadctrl2 = <0x121113d>;
				nvidia,emc-zcal-cnt-long = <0x42>;
				nvidia,emc-zcal-interval = <0x20000>;
				nvidia,emc-configuration = <0x1b 0x9b 0x0 0x13 0x7 0x7 0xb 0x3 0x10 0x7 0x7 0x2 0x2 0x0 0x5 0x5 0xa 0x2 0x0 0x3 0xb 0x70000 0x3 0x0 0x0 0x0 0x0 0x2 0x12 0x16 0x18 0x1208 0x0 0x482 0x2 0xd 0x1 0x0 0x97 0x15 0xa3 0x200 0x4 0x5 0x4 0x13 0x0 0x6 0x6 0x1248 0x0 0x0 0x0 0x104ab098 0xe00e00b1 0x8000 0xa 0xa 0xa 0xa 0xa 0xa 0xa 0xa 0xa 0xa 0xa 0xa 0xa 0xa 0xa 0xa 0x0 0x0 0x0 0x0 0x0 0x0 0x0 0x0 0x48000 0x48000 0x0 0x48000 0x48000 0x0 0x0 0x0 0x0 0x0 0x0 0x0 0x0 0x0 0x0 0x0 0x0 0x0 0x0 0x0 0x0 0x0 0x0 0x0 0x0 0x0 0x0 0x0 0x0 0x0 0xd 0xd 0xd 0xd 0xd 0xd 0xd 0xd 0x100002a0 0x0 0x111111 0x0 0x0 0x77ffc085 0x505 0x81f1f108 0x7070004 0x0 0x16eeeee 0x51451420 0x514514 0x514514 0x51451400 0x606003f 0x0 0x0 0x100 0x127000e 0x0 0x3 0x40a0 0x800024aa 0xe>;
			};

			timing-792000000 {
				clock-frequency = <0x2f34f600>;
				nvidia,emc-auto-cal-config = <0xa1430000>;
				nvidia,emc-auto-cal-config2 = <0x0>;
				nvidia,emc-auto-cal-config3 = <0x0>;
				nvidia,emc-auto-cal-interval = <0x1fffff>;
				nvidia,emc-bgbias-ctl0 = <0x0>;
				nvidia,emc-cfg = <0x73300000>;
				nvidia,emc-cfg-2 = <0x89d>;
				nvidia,emc-ctt-term-ctrl = <0x802>;
				nvidia,emc-mode-1 = <0x80100002>;
				nvidia,emc-mode-2 = <0x80200018>;
				nvidia,emc-mode-4 = <0x0>;
				nvidia,emc-mode-reset = <0x80000d71>;
				nvidia,emc-mrs-wait-cnt = <0xf7000e>;
				nvidia,emc-sel-dpd-ctrl = <0x40000>;
				nvidia,emc-xm2dqspadctrl2 = <0x120113d>;
				nvidia,emc-zcal-cnt-long = <0x42>;
				nvidia,emc-zcal-interval = <0x20000>;
				nvidia,emc-configuration = <0x24 0xcd 0x0 0x19 0xa 0x8 0xd 0x4 0x13 0xa 0xa 0x4 0x2 0x0 0x6 0x6 0xb 0x2 0x0 0x2 0xd 0x80000 0x4 0x0 0x0 0x0 0x0 0x1 0x14 0x18 0x1a 0x17e2 0x0 0x5f8 0x3 0x11 0x1 0x0 0xc7 0x18 0xd7 0x200 0x5 0x6 0x5 0x19 0x0 0x8 0x8 0x1822 0x0 0x0 0x0 0x104ab098 0xe00700b1 0x8000 0x7fc008 0x7fc008 0x7fc008 0x7fc008 0x7fc008 0x7fc008 0x7fc008 0x7fc008 0x7fc008 0x7fc008 0x7fc008 0x7fc008 0x7fc008 0x7fc008 0x7fc008 0x7fc008 0x0 0x0 0x0 0x0 0x0 0x0 0x0 0x0 0x34000 0x34000 0x0 0x34000 0x34000 0x0 0x0 0x0 0x0 0x0 0x0 0x0 0x0 0x0 0x5 0x5 0x5 0x5 0x5 0x5 0x5 0x5 0x5 0x5 0x5 0x5 0x5 0x5 0x5 0x5 0xa 0xa 0xa 0xa 0xa 0xa 0xa 0xa 0x100002a0 0x0 0x111111 0x0 0x0 0x77ffc085 0x0 0x81f1f108 0x7070004 0x0 0x16eeeee 0x61861820 0x514514 0x514514 0x61861800 0x606003f 0x0 0x0 0x100 0xf7000e 0x0 0x4 0x4080 0x80003012 0xf>;
			};

			timing-924000000 {
				clock-frequency = <0x37131f00>;
				nvidia,emc-auto-cal-config = <0xa1430303>;
				nvidia,emc-auto-cal-config2 = <0x0>;
				nvidia,emc-auto-cal-config3 = <0x0>;
				nvidia,emc-auto-cal-interval = <0x1fffff>;
				nvidia,emc-bgbias-ctl0 = <0x0>;
				nvidia,emc-cfg = <0x73300000>;
				nvidia,emc-cfg-2 = <0x89d>;
				nvidia,emc-ctt-term-ctrl = <0x802>;
				nvidia,emc-mode-1 = <0x80100002>;
				nvidia,emc-mode-2 = <0x80200020>;
				nvidia,emc-mode-4 = <0x0>;
				nvidia,emc-mode-reset = <0x80000f15>;
				nvidia,emc-mrs-wait-cnt = <0xcd000e>;
				nvidia,emc-sel-dpd-ctrl = <0x40000>;
				nvidia,emc-xm2dqspadctrl2 = <0x120113d>;
				nvidia,emc-zcal-cnt-long = <0x4c>;
				nvidia,emc-zcal-interval = <0x20000>;
				nvidia,emc-configuration = <0x2b 0xf0 0x0 0x1e 0xb 0x9 0xf 0x5 0x16 0xb 0xb 0x4 0x2 0x0 0x7 0x7 0xd 0x2 0x0 0x2 0xf 0xa0000 0x4 0x0 0x0 0x0 0x0 0x1 0x16 0x1a 0x1c 0x1be7 0x0 0x6f9 0x4 0x15 0x1 0x0 0xe7 0x1b 0xfb 0x200 0x6 0x7 0x6 0x1e 0x0 0xa 0xa 0x1c28 0x0 0x0 0x0 0x104ab898 0xe00400b1 0x8000 0x7f800a 0x7f800a 0x7f800a 0x7f800a 0x7f800a 0x7f800a 0x7f800a 0x7f800a 0x7f800a 0x7f800a 0x7f800a 0x7f800a 0x7f800a 0x7f800a 0x7f800a 0x7f800a 0x0 0x0 0x0 0x0 0x0 0x0 0x0 0x0 0x2c000 0x2c000 0x0 0x2c000 0x2c000 0x0 0x0 0x0 0x0 0x0 0x0 0x0 0x0 0x0 0x4 0x4 0x4 0x4 0x4 0x4 0x4 0x4 0x4 0x4 0x4 0x4 0x4 0x4 0x4 0x4 0x8 0x8 0x8 0x8 0x8 0x8 0x8 0x8 0x100002a0 0x0 0x111111 0x0 0x0 0x77ffc085 0x0 0x81f1f108 0x7070004 0x0 0x16eeeee 0x5d75d720 0x514514 0x514514 0x5d75d700 0x606003f 0x0 0x0 0x128 0xcd000e 0x0 0x4 0x4080 0x800037ea 0x11>;
			};
		};
	};

	sata@0,70020000 {
		compatible = "nvidia,tegra124-ahci";
		reg = <0x0 0x70027000 0x0 0x2000 0x0 0x70020000 0x0 0x7000>;
		interrupts = <0x0 0x17 0x4>;
		clocks = <0x2 0x7c 0x2 0x7b 0x2 0x10d 0x2 0xe7>;
		clock-names = "sata", "sata-oob", "cml1", "pll_e";
		resets = <0x2 0x7c 0x2 0x7b 0x2 0x81>;
		reset-names = "sata", "sata-oob", "sata-cold";
		phys = <0x3 0x1>;
		phy-names = "sata-phy";
		status = "okay";
		hvdd-supply = <0x5>;
		vddio-supply = <0x4>;
		avdd-supply = <0x4>;
		target-5v-supply = <0x18>;
		target-12v-supply = <0x19>;
	};

	hda@0,70030000 {
		compatible = "nvidia,tegra124-hda", "nvidia,tegra30-hda";
		reg = <0x0 0x70030000 0x0 0x10000>;
		interrupts = <0x0 0x51 0x4>;
		clocks = <0x2 0x7d 0x2 0x80 0x2 0x6f>;
		clock-names = "hda", "hda2hdmi", "hda2codec_2x";
		resets = <0x2 0x7d 0x2 0x80 0x2 0x6f>;
		reset-names = "hda", "hda2hdmi", "hda2codec_2x";
		status = "okay";
	};

	padctl@0,7009f000 {
		compatible = "nvidia,tegra124-xusb-padctl";
		reg = <0x0 0x7009f000 0x0 0x1000>;
		resets = <0x2 0x8e>;
		reset-names = "padctl";
		#phy-cells = <0x1>;
		pinctrl-0 = <0x1a>;
		pinctrl-names = "default";
		linux,phandle = <0x3>;
		phandle = <0x3>;

		pinmux {
			linux,phandle = <0x1a>;
			phandle = <0x1a>;

			usb3 {
				nvidia,lanes = "pcie-0", "pcie-1";
				nvidia,function = "usb3";
				nvidia,iddq = <0x0>;
			};

			pcie {
				nvidia,lanes = "pcie-2", "pcie-3", "pcie-4";
				nvidia,function = "pcie";
				nvidia,iddq = <0x0>;
			};

			sata {
				nvidia,lanes = "sata-0";
				nvidia,function = "sata";
				nvidia,iddq = <0x0>;
			};
		};
	};

	sdhci@0,700b0000 {
		compatible = "nvidia,tegra124-sdhci";
		reg = <0x0 0x700b0000 0x0 0x200>;
		interrupts = <0x0 0xe 0x4>;
		clocks = <0x2 0xe>;
		resets = <0x2 0xe>;
		reset-names = "sdhci";
		status = "disabled";
	};

	sdhci@0,700b0200 {
		compatible = "nvidia,tegra124-sdhci";
		reg = <0x0 0x700b0200 0x0 0x200>;
		interrupts = <0x0 0xf 0x4>;
		clocks = <0x2 0x9>;
		resets = <0x2 0x9>;
		reset-names = "sdhci";
		status = "disabled";
	};

	sdhci@0,700b0400 {
		compatible = "nvidia,tegra124-sdhci";
		reg = <0x0 0x700b0400 0x0 0x200>;
		interrupts = <0x0 0x13 0x4>;
		clocks = <0x2 0x45>;
		resets = <0x2 0x45>;
		reset-names = "sdhci";
		status = "okay";
		cd-gpios = <0xc 0xaa 0x1>;
		power-gpios = <0xc 0x88 0x0>;
		wp-gpios = <0xc 0x84 0x0>;
		bus-width = <0x4>;
		vqmmc-supply = <0x1b>;
	};

	sdhci@0,700b0600 {
		compatible = "nvidia,tegra124-sdhci";
		reg = <0x0 0x700b0600 0x0 0x200>;
		interrupts = <0x0 0x1f 0x4>;
		clocks = <0x2 0xf>;
		resets = <0x2 0xf>;
		reset-names = "sdhci";
		status = "okay";
		bus-width = <0x8>;
		non-removable;
	};

	thermal-sensor@0,700e2000 {
		compatible = "nvidia,tegra124-soctherm";
		reg = <0x0 0x700e2000 0x0 0x1000>;
		interrupts = <0x0 0x30 0x4>;
		clocks = <0x2 0x64 0x2 0x4e>;
		clock-names = "tsensor", "soctherm";
		resets = <0x2 0x4e>;
		reset-names = "soctherm";
		#thermal-sensor-cells = <0x1>;
		linux,phandle = <0x26>;
		phandle = <0x26>;
	};

	clock@0,70110000 {
		compatible = "nvidia,tegra124-dfll";
		reg = <0x0 0x70110000 0x0 0x100 0x0 0x70110000 0x0 0x100 0x0 0x70110100 0x0 0x100 0x0 0x70110200 0x0 0x100>;
		interrupts = <0x0 0x3e 0x4>;
		clocks = <0x2 0x109 0x2 0x108 0x2 0x2f>;
		clock-names = "soc", "ref", "i2c";
		resets = <0x2 0xc0>;
		reset-names = "dvco";
		#clock-cells = <0x0>;
		clock-output-names = "dfllCPU_out";
		nvidia,sample-rate = <0x30d4>;
		nvidia,droop-ctrl = <0xf00>;
		nvidia,force-mode = <0x1>;
		nvidia,cf = <0xa>;
		nvidia,ci = <0x0>;
		nvidia,cg = <0x2>;
		status = "okay";
		vdd-cpu-supply = <0x1c>;
		nvidia,i2c-fs-rate = <0x61a80>;
		linux,phandle = <0x21>;
		phandle = <0x21>;
	};

	ahub@0,70300000 {
		compatible = "nvidia,tegra124-ahub";
		reg = <0x0 0x70300000 0x0 0x200 0x0 0x70300800 0x0 0x800 0x0 0x70300200 0x0 0x600>;
		interrupts = <0x0 0x67 0x4>;
		clocks = <0x2 0x6a 0x2 0x6b>;
		clock-names = "d_audio", "apbif";
		resets = <0x2 0x6a 0x2 0x6b 0x2 0x1e 0x2 0xb 0x2 0x12 0x2 0x65 0x2 0x66 0x2 0x6c 0x2 0x6d 0x2 0x6e 0x2 0xa 0x2 0x99 0x2 0xb9 0x2 0x9a 0x2 0xb4 0x2 0xba 0x2 0xbb 0x2 0xbc 0x2 0xbd 0x2 0xbe 0x2 0xbf>;
		reset-names = "d_audio", "apbif", "i2s0", "i2s1", "i2s2", "i2s3", "i2s4", "dam0", "dam1", "dam2", "spdif", "amx", "amx1", "adx", "adx1", "afc0", "afc1", "afc2", "afc3", "afc4", "afc5";
		dmas = <0x10 0x1 0x10 0x1 0x10 0x2 0x10 0x2 0x10 0x3 0x10 0x3 0x10 0x4 0x10 0x4 0x10 0x6 0x10 0x6 0x10 0x7 0x10 0x7 0x10 0xc 0x10 0xc 0x10 0xd 0x10 0xd 0x10 0xe 0x10 0xe 0x10 0x1d 0x10 0x1d>;
		dma-names = "rx0", "tx0", "rx1", "tx1", "rx2", "tx2", "rx3", "tx3", "rx4", "tx4", "rx5", "tx5", "rx6", "tx6", "rx7", "tx7", "rx8", "tx8", "rx9", "tx9";
		ranges;
		#address-cells = <0x2>;
		#size-cells = <0x2>;

		i2s@0,70301000 {
			compatible = "nvidia,tegra124-i2s";
			reg = <0x0 0x70301000 0x0 0x100>;
			nvidia,ahub-cif-ids = <0x4 0x4>;
			clocks = <0x2 0x1e>;
			resets = <0x2 0x1e>;
			reset-names = "i2s";
			status = "disabled";
		};

		i2s@0,70301100 {
			compatible = "nvidia,tegra124-i2s";
			reg = <0x0 0x70301100 0x0 0x100>;
			nvidia,ahub-cif-ids = <0x5 0x5>;
			clocks = <0x2 0xb>;
			resets = <0x2 0xb>;
			reset-names = "i2s";
			status = "okay";
			linux,phandle = <0x29>;
			phandle = <0x29>;
		};

		i2s@0,70301200 {
			compatible = "nvidia,tegra124-i2s";
			reg = <0x0 0x70301200 0x0 0x100>;
			nvidia,ahub-cif-ids = <0x6 0x6>;
			clocks = <0x2 0x12>;
			resets = <0x2 0x12>;
			reset-names = "i2s";
			status = "disabled";
		};

		i2s@0,70301300 {
			compatible = "nvidia,tegra124-i2s";
			reg = <0x0 0x70301300 0x0 0x100>;
			nvidia,ahub-cif-ids = <0x7 0x7>;
			clocks = <0x2 0x65>;
			resets = <0x2 0x65>;
			reset-names = "i2s";
			status = "disabled";
		};

		i2s@0,70301400 {
			compatible = "nvidia,tegra124-i2s";
			reg = <0x0 0x70301400 0x0 0x100>;
			nvidia,ahub-cif-ids = <0x8 0x8>;
			clocks = <0x2 0x66>;
			resets = <0x2 0x66>;
			reset-names = "i2s";
			status = "disabled";
		};
	};

	usb@0,7d000000 {
		compatible = "nvidia,tegra124-ehci", "nvidia,tegra30-ehci", "usb-ehci";
		reg = <0x0 0x7d000000 0x0 0x4000>;
		interrupts = <0x0 0x14 0x4>;
		phy_type = "utmi";
		clocks = <0x2 0x16>;
		resets = <0x2 0x16>;
		reset-names = "usb";
		nvidia,phy = <0x1d>;
		status = "disabled";
	};

	usb-phy@0,7d000000 {
		compatible = "nvidia,tegra124-usb-phy", "nvidia,tegra30-usb-phy";
		reg = <0x0 0x7d000000 0x0 0x4000 0x0 0x7d000000 0x0 0x4000>;
		phy_type = "utmi";
		clocks = <0x2 0x16 0x2 0xde 0x2 0x16>;
		clock-names = "reg", "pll_u", "utmi-pads";
		resets = <0x2 0x16 0x2 0x16>;
		reset-names = "usb", "utmi-pads";
		nvidia,hssync-start-delay = <0x0>;
		nvidia,idle-wait-delay = <0x11>;
		nvidia,elastic-limit = <0x10>;
		nvidia,term-range-adj = <0x6>;
		nvidia,xcvr-setup = <0x9>;
		nvidia,xcvr-lsfslew = <0x0>;
		nvidia,xcvr-lsrslew = <0x3>;
		nvidia,hssquelch-level = <0x2>;
		nvidia,hsdiscon-level = <0x5>;
		nvidia,xcvr-hsslew = <0xc>;
		nvidia,has-utmi-pad-registers;
		status = "disabled";
		linux,phandle = <0x1d>;
		phandle = <0x1d>;
	};

	usb@0,7d004000 {
		compatible = "nvidia,tegra124-ehci", "nvidia,tegra30-ehci", "usb-ehci";
		reg = <0x0 0x7d004000 0x0 0x4000>;
		interrupts = <0x0 0x15 0x4>;
		phy_type = "utmi";
		clocks = <0x2 0x3a>;
		resets = <0x2 0x3a>;
		reset-names = "usb";
		nvidia,phy = <0x1e>;
		status = "okay";
	};

	usb-phy@0,7d004000 {
		compatible = "nvidia,tegra124-usb-phy", "nvidia,tegra30-usb-phy";
		reg = <0x0 0x7d004000 0x0 0x4000 0x0 0x7d000000 0x0 0x4000>;
		phy_type = "utmi";
		clocks = <0x2 0x3a 0x2 0xde 0x2 0x16>;
		clock-names = "reg", "pll_u", "utmi-pads";
		resets = <0x2 0x3a 0x2 0x16>;
		reset-names = "usb", "utmi-pads";
		nvidia,hssync-start-delay = <0x0>;
		nvidia,idle-wait-delay = <0x11>;
		nvidia,elastic-limit = <0x10>;
		nvidia,term-range-adj = <0x6>;
		nvidia,xcvr-setup = <0x9>;
		nvidia,xcvr-lsfslew = <0x0>;
		nvidia,xcvr-lsrslew = <0x3>;
		nvidia,hssquelch-level = <0x2>;
		nvidia,hsdiscon-level = <0x5>;
		nvidia,xcvr-hsslew = <0xc>;
		status = "okay";
		linux,phandle = <0x1e>;
		phandle = <0x1e>;
	};

	usb@0,7d008000 {
		compatible = "nvidia,tegra124-ehci", "nvidia,tegra30-ehci", "usb-ehci";
		reg = <0x0 0x7d008000 0x0 0x4000>;
		interrupts = <0x0 0x61 0x4>;
		phy_type = "utmi";
		clocks = <0x2 0x3b>;
		resets = <0x2 0x3b>;
		reset-names = "usb";
		nvidia,phy = <0x1f>;
		status = "okay";
	};

	usb-phy@0,7d008000 {
		compatible = "nvidia,tegra124-usb-phy", "nvidia,tegra30-usb-phy";
		reg = <0x0 0x7d008000 0x0 0x4000 0x0 0x7d000000 0x0 0x4000>;
		phy_type = "utmi";
		clocks = <0x2 0x3b 0x2 0xde 0x2 0x16>;
		clock-names = "reg", "pll_u", "utmi-pads";
		resets = <0x2 0x3b 0x2 0x16>;
		reset-names = "usb", "utmi-pads";
		nvidia,hssync-start-delay = <0x0>;
		nvidia,idle-wait-delay = <0x11>;
		nvidia,elastic-limit = <0x10>;
		nvidia,term-range-adj = <0x6>;
		nvidia,xcvr-setup = <0x9>;
		nvidia,xcvr-lsfslew = <0x0>;
		nvidia,xcvr-lsrslew = <0x3>;
		nvidia,hssquelch-level = <0x2>;
		nvidia,hsdiscon-level = <0x5>;
		nvidia,xcvr-hsslew = <0xc>;
		status = "okay";
		vbus-supply = <0x20>;
		linux,phandle = <0x1f>;
		phandle = <0x1f>;
	};

	cpus {
		#address-cells = <0x1>;
		#size-cells = <0x0>;

		cpu@0 {
			device_type = "cpu";
			compatible = "arm,cortex-a15";
			reg = <0x0>;
			clocks = <0x2 0x106 0x2 0x107 0x2 0xe3 0x2 0xd3 0x21>;
			clock-names = "cpu_g", "cpu_lp", "pll_x", "pll_p", "dfll";
			clock-latency = <0x493e0>;
			vdd-cpu-supply = <0x1c>;
			linux,phandle = <0x22>;
			phandle = <0x22>;
		};

		cpu@1 {
			device_type = "cpu";
			compatible = "arm,cortex-a15";
			reg = <0x1>;
			linux,phandle = <0x23>;
			phandle = <0x23>;
		};

		cpu@2 {
			device_type = "cpu";
			compatible = "arm,cortex-a15";
			reg = <0x2>;
			linux,phandle = <0x24>;
			phandle = <0x24>;
		};

		cpu@3 {
			device_type = "cpu";
			compatible = "arm,cortex-a15";
			reg = <0x3>;
			linux,phandle = <0x25>;
			phandle = <0x25>;
		};
	};

	pmu {
		compatible = "arm,cortex-a15-pmu";
		interrupts = <0x0 0x90 0x4 0x0 0x91 0x4 0x0 0x92 0x4 0x0 0x93 0x4>;
		interrupt-affinity = <0x22 0x23 0x24 0x25>;
	};

	thermal-zones {

		cpu {
			polling-delay-passive = <0x3e8>;
			polling-delay = <0x3e8>;
			thermal-sensors = <0x26 0x0>;
		};

		mem {
			polling-delay-passive = <0x3e8>;
			polling-delay = <0x3e8>;
			thermal-sensors = <0x26 0x1>;
		};

		gpu {
			polling-delay-passive = <0x3e8>;
			polling-delay = <0x3e8>;
			thermal-sensors = <0x26 0x2>;
		};

		pllx {
			polling-delay-passive = <0x3e8>;
			polling-delay = <0x3e8>;
			thermal-sensors = <0x26 0x3>;
		};
	};

	timer {
		compatible = "arm,armv7-timer";
		interrupts = <0x1 0xd 0xf08 0x1 0xe 0xf08 0x1 0xb 0xf08 0x1 0xa 0xf08>;
		interrupt-parent = <0x1>;
	};

	clocks {
		compatible = "simple-bus";
		#address-cells = <0x1>;
		#size-cells = <0x0>;

		clock@0 {
			compatible = "fixed-clock";
			reg = <0x0>;
			#clock-cells = <0x0>;
			clock-frequency = <0x8000>;
			linux,phandle = <0x17>;
			phandle = <0x17>;
		};
	};

	gpio-keys {
		compatible = "gpio-keys";

		power {
			label = "Power";
			gpios = <0xc 0x80 0x1>;
			linux,code = <0x74>;
			debounce-interval = <0xa>;
			gpio-key,wakeup;
		};
	};

	regulators {
		compatible = "simple-bus";
		#address-cells = <0x1>;
		#size-cells = <0x0>;

		regulator@0 {
			compatible = "regulator-fixed";
			reg = <0x0>;
			regulator-name = "+VDD_MUX";
			regulator-min-microvolt = <0xb71b00>;
			regulator-max-microvolt = <0xb71b00>;
			regulator-always-on;
			regulator-boot-on;
			linux,phandle = <0x27>;
			phandle = <0x27>;
		};

		regulator@1 {
			compatible = "regulator-fixed";
			reg = <0x1>;
			regulator-name = "+5V_SYS";
			regulator-min-microvolt = <0x4c4b40>;
			regulator-max-microvolt = <0x4c4b40>;
			regulator-always-on;
			regulator-boot-on;
			vin-supply = <0x27>;
			linux,phandle = <0x12>;
			phandle = <0x12>;
		};

		regulator@2 {
			compatible = "regulator-fixed";
			reg = <0x2>;
			regulator-name = "+3.3V_SYS";
			regulator-min-microvolt = <0x325aa0>;
			regulator-max-microvolt = <0x325aa0>;
			regulator-always-on;
			regulator-boot-on;
			vin-supply = <0x27>;
			linux,phandle = <0x16>;
			phandle = <0x16>;
		};

		regulator@3 {
			compatible = "regulator-fixed";
			reg = <0x3>;
			regulator-name = "+3.3V_RUN";
			regulator-min-microvolt = <0x325aa0>;
			regulator-max-microvolt = <0x325aa0>;
			regulator-always-on;
			regulator-boot-on;
			gpio = <0x28 0x1 0x0>;
			enable-active-high;
			vin-supply = <0x16>;
			linux,phandle = <0x14>;
			phandle = <0x14>;
		};

		regulator@4 {
			compatible = "regulator-fixed";
			reg = <0x4>;
			regulator-name = "+3.3V_AVDD_HDMI_AP_GATED";
			regulator-min-microvolt = <0x325aa0>;
			regulator-max-microvolt = <0x325aa0>;
			vin-supply = <0x14>;
			linux,phandle = <0xa>;
			phandle = <0xa>;
		};

		regulator@7 {
			compatible = "regulator-fixed";
			reg = <0x7>;
			regulator-name = "+USB0_VBUS_SW";
			regulator-min-microvolt = <0x4c4b40>;
			regulator-max-microvolt = <0x4c4b40>;
			gpio = <0xc 0x6c 0x0>;
			enable-active-high;
			gpio-open-drain;
			vin-supply = <0x12>;
		};

		regulator@8 {
			compatible = "regulator-fixed";
			reg = <0x8>;
			regulator-name = "+5V_USB_HS";
			regulator-min-microvolt = <0x4c4b40>;
			regulator-max-microvolt = <0x4c4b40>;
			gpio = <0xc 0x6d 0x0>;
			enable-active-high;
			gpio-open-drain;
			vin-supply = <0x12>;
			linux,phandle = <0x20>;
			phandle = <0x20>;
		};

		regulator@10 {
			compatible = "regulator-fixed";
			reg = <0xa>;
			regulator-name = "+3.3V_LP0";
			regulator-min-microvolt = <0x325aa0>;
			regulator-max-microvolt = <0x325aa0>;
			regulator-always-on;
			regulator-boot-on;
			gpio = <0x28 0x2 0x0>;
			enable-active-high;
			vin-supply = <0x16>;
			linux,phandle = <0x5>;
			phandle = <0x5>;
		};

		regulator@11 {
			compatible = "regulator-fixed";
			reg = <0xb>;
			regulator-name = "+1.05V_RUN_AVDD_HDMI_PLL";
			regulator-min-microvolt = <0x100590>;
			regulator-max-microvolt = <0x100590>;
			gpio = <0xc 0x3f 0x1>;
			vin-supply = <0x4>;
			linux,phandle = <0x9>;
			phandle = <0x9>;
		};

		regulator@12 {
			compatible = "regulator-fixed";
			reg = <0xc>;
			regulator-name = "+5V_HDMI_CON";
			regulator-min-microvolt = <0x4c4b40>;
			regulator-max-microvolt = <0x4c4b40>;
			gpio = <0xc 0x56 0x0>;
			enable-active-high;
			vin-supply = <0x12>;
			linux,phandle = <0x8>;
			phandle = <0x8>;
		};

		regulator@13 {
			compatible = "regulator-fixed";
			reg = <0xd>;
			regulator-name = "+5V_SATA";
			regulator-min-microvolt = <0x4c4b40>;
			regulator-max-microvolt = <0x4c4b40>;
			gpio = <0xc 0xf2 0x0>;
			enable-active-high;
			vin-supply = <0x12>;
			linux,phandle = <0x18>;
			phandle = <0x18>;
		};

		regulator@14 {
			compatible = "regulator-fixed";
			reg = <0xe>;
			regulator-name = "+12V_SATA";
			regulator-min-microvolt = <0xb71b00>;
			regulator-max-microvolt = <0xb71b00>;
			gpio = <0xc 0xf2 0x0>;
			enable-active-high;
			vin-supply = <0x27>;
			linux,phandle = <0x19>;
			phandle = <0x19>;
		};
	};

	sound {
		compatible = "nvidia,tegra-audio-rt5640-jetson-tk1", "nvidia,tegra-audio-rt5640";
		nvidia,model = "NVIDIA Tegra Jetson TK1";
		nvidia,audio-routing = "Headphones", "HPOR", "Headphones", "HPOL", "Mic Jack", "MICBIAS1", "IN2P", "Mic Jack";
		nvidia,i2s-controller = <0x29>;
		nvidia,audio-codec = <0x2a>;
		nvidia,hp-det-gpios = <0xc 0x8f 0x1>;
		clocks = <0x2 0xd8 0x2 0xd9 0x2 0x78>;
		clock-names = "pll_a", "pll_a_out0", "mclk";
	};
};
